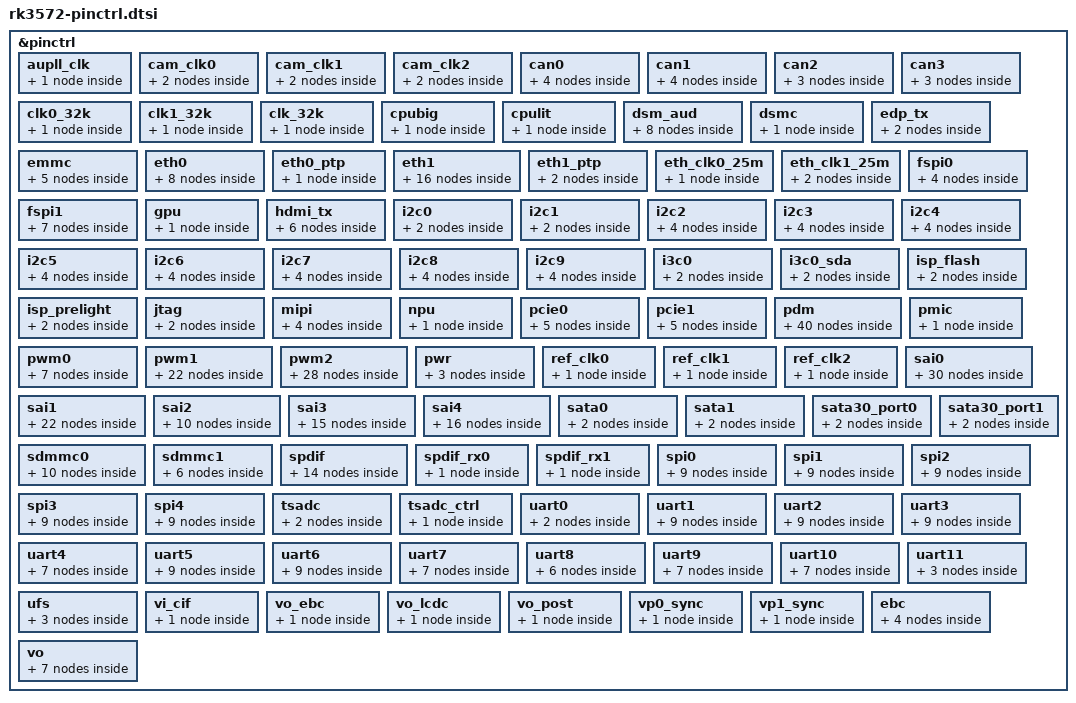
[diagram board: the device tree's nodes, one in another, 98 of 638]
// SPDX-License-Identifier: (GPL-2.0+ OR MIT)
/*
 * Copyright (c) 2025 Rockchip Electronics Co., Ltd.
 */

#include <dt-bindings/pinctrl/rockchip.h>
#include "rockchip-pinconf.dtsi"

&pinctrl {
	aupll_clk {
		/omit-if-no-ref/
		aupll_clk_pins: aupll-clk-pins {
			rockchip,pins =
				<0 RK_PA0 3 &pcfg_pull_none>;
		};
	};

	cam_clk0 {
		/omit-if-no-ref/
		cam_clk0m0_clk0_pins: cam-clk0m0-clk0-pins {
			rockchip,pins =
				<3 RK_PD7 1 &pcfg_pull_none>;
		};

		/omit-if-no-ref/
		cam_clk0m1_clk0_pins: cam-clk0m1-clk0-pins {
			rockchip,pins =
				<2 RK_PD4 3 &pcfg_pull_none>;
		};
	};

	cam_clk1 {
		/omit-if-no-ref/
		cam_clk1m0_clk1_pins: cam-clk1m0-clk1-pins {
			rockchip,pins =
				<4 RK_PA0 1 &pcfg_pull_none>;
		};

		/omit-if-no-ref/
		cam_clk1m1_clk1_pins: cam-clk1m1-clk1-pins {
			rockchip,pins =
				<2 RK_PD5 3 &pcfg_pull_none>;
		};
	};

	cam_clk2 {
		/omit-if-no-ref/
		cam_clk2m0_clk2_pins: cam-clk2m0-clk2-pins {
			rockchip,pins =
				<4 RK_PA1 1 &pcfg_pull_none>;
		};

		/omit-if-no-ref/
		cam_clk2m1_clk2_pins: cam-clk2m1-clk2-pins {
			rockchip,pins =
				<2 RK_PD6 3 &pcfg_pull_none>;
		};
	};

	can0 {
		/omit-if-no-ref/
		can0m0_pins: can0m0-pins {
			rockchip,pins =
				<2 RK_PA2 13 &pcfg_pull_none>,
				<2 RK_PA3 13 &pcfg_pull_none>;
		};

		/omit-if-no-ref/
		can0m1_pins: can0m1-pins {
			rockchip,pins =
				<4 RK_PB3 14 &pcfg_pull_none>,
				<4 RK_PB2 14 &pcfg_pull_none>;
		};

		/omit-if-no-ref/
		can0m2_pins: can0m2-pins {
			rockchip,pins =
				<2 RK_PB3 13 &pcfg_pull_none>,
				<2 RK_PB1 13 &pcfg_pull_none>;
		};

		/omit-if-no-ref/
		can0m3_pins: can0m3-pins {
			rockchip,pins =
				<3 RK_PC1 13 &pcfg_pull_none>,
				<3 RK_PC4 13 &pcfg_pull_none>;
		};
	};

	can1 {
		/omit-if-no-ref/
		can1m0_pins: can1m0-pins {
			rockchip,pins =
				<2 RK_PA0 13 &pcfg_pull_none>,
				<2 RK_PA1 13 &pcfg_pull_none>;
		};

		/omit-if-no-ref/
		can1m1_pins: can1m1-pins {
			rockchip,pins =
				<4 RK_PB7 13 &pcfg_pull_none>,
				<4 RK_PB6 13 &pcfg_pull_none>;
		};

		/omit-if-no-ref/
		can1m2_pins: can1m2-pins {
			rockchip,pins =
				<2 RK_PC2 13 &pcfg_pull_none>,
				<2 RK_PC3 13 &pcfg_pull_none>;
		};

		/omit-if-no-ref/
		can1m3_pins: can1m3-pins {
			rockchip,pins =
				<2 RK_PD7 13 &pcfg_pull_none>,
				<2 RK_PD6 13 &pcfg_pull_none>;
		};
	};

	can2 {
		/omit-if-no-ref/
		can2m0_pins: can2m0-pins {
			rockchip,pins =
				<2 RK_PA4 13 &pcfg_pull_none>,
				<2 RK_PA5 13 &pcfg_pull_none>;
		};

		/omit-if-no-ref/
		can2m1_pins: can2m1-pins {
			rockchip,pins =
				<1 RK_PC2 13 &pcfg_pull_none>,
				<1 RK_PC3 13 &pcfg_pull_none>;
		};

		/omit-if-no-ref/
		can2m2_pins: can2m2-pins {
			rockchip,pins =
				<3 RK_PB7 13 &pcfg_pull_none>,
				<3 RK_PC0 13 &pcfg_pull_none>;
		};
	};

	can3 {
		/omit-if-no-ref/
		can3m0_pins: can3m0-pins {
			rockchip,pins =
				<1 RK_PD6 13 &pcfg_pull_none>,
				<1 RK_PD5 13 &pcfg_pull_none>;
		};

		/omit-if-no-ref/
		can3m1_pins: can3m1-pins {
			rockchip,pins =
				<2 RK_PD5 13 &pcfg_pull_none>,
				<2 RK_PD4 13 &pcfg_pull_none>;
		};

		/omit-if-no-ref/
		can3m2_pins: can3m2-pins {
			rockchip,pins =
				<3 RK_PC2 13 &pcfg_pull_none>,
				<3 RK_PC3 13 &pcfg_pull_none>;
		};
	};

	clk0_32k {
		/omit-if-no-ref/
		clk0_32k_pins: clk0-32k-pins {
			rockchip,pins =
				<0 RK_PA2 10 &pcfg_pull_none>;
		};
	};

	clk1_32k {
		/omit-if-no-ref/
		clk1_32k_pins: clk1-32k-pins {
			rockchip,pins =
				<1 RK_PD5 7 &pcfg_pull_none>;
		};
	};

	clk_32k {
		/omit-if-no-ref/
		clk_32k_pins: clk-32k-pins {
			rockchip,pins =
				<0 RK_PA2 9 &pcfg_pull_none>;
		};
	};

	cpubig {
		/omit-if-no-ref/
		cpubig_pins: cpubig-pins {
			rockchip,pins =
				<0 RK_PD2 13 &pcfg_pull_none>;
		};
	};

	cpulit {
		/omit-if-no-ref/
		cpulit_pins: cpulit-pins {
			rockchip,pins =
				<0 RK_PC0 13 &pcfg_pull_none>;
		};
	};

	dsm_aud {
		/omit-if-no-ref/
		dsm_audm0_ln_pins: dsm-audm0-ln-pins {
			rockchip,pins =
				<2 RK_PA1 3 &pcfg_pull_none>;
		};

		/omit-if-no-ref/
		dsm_audm0_lp_pins: dsm-audm0-lp-pins {
			rockchip,pins =
				<2 RK_PA0 3 &pcfg_pull_none>;
		};

		/omit-if-no-ref/
		dsm_audm0_rn_pins: dsm-audm0-rn-pins {
			rockchip,pins =
				<2 RK_PA3 3 &pcfg_pull_none>;
		};

		/omit-if-no-ref/
		dsm_audm0_rp_pins: dsm-audm0-rp-pins {
			rockchip,pins =
				<2 RK_PA2 3 &pcfg_pull_none>;
		};

		/omit-if-no-ref/
		dsm_audm1_ln_pins: dsm-audm1-ln-pins {
			rockchip,pins =
				<4 RK_PB1 3 &pcfg_pull_none>;
		};

		/omit-if-no-ref/
		dsm_audm1_lp_pins: dsm-audm1-lp-pins {
			rockchip,pins =
				<4 RK_PB0 3 &pcfg_pull_none>;
		};

		/omit-if-no-ref/
		dsm_audm1_rn_pins: dsm-audm1-rn-pins {
			rockchip,pins =
				<4 RK_PB3 3 &pcfg_pull_none>;
		};

		/omit-if-no-ref/
		dsm_audm1_rp_pins: dsm-audm1-rp-pins {
			rockchip,pins =
				<4 RK_PB2 3 &pcfg_pull_none>;
		};
	};

	dsmc {
		/omit-if-no-ref/
		dsmc_bus16_pins: dsmc-bus16-pins {
			rockchip,pins =
				<3 RK_PD6 2 &pcfg_pull_none>,
				<3 RK_PD5 2 &pcfg_pull_none>,
				<3 RK_PD3 2 &pcfg_pull_none>,
				<3 RK_PB0 2 &pcfg_pull_none>,
				<3 RK_PD1 2 &pcfg_pull_none>,
				<3 RK_PD2 2 &pcfg_pull_none>,
				<3 RK_PD4 2 &pcfg_pull_none>,
				<3 RK_PD0 2 &pcfg_pull_none>,
				<3 RK_PC7 2 &pcfg_pull_none>,
				<3 RK_PC6 2 &pcfg_pull_none>,
				<3 RK_PC5 2 &pcfg_pull_none>,
				<3 RK_PC4 2 &pcfg_pull_none>,
				<3 RK_PC1 2 &pcfg_pull_none>,
				<3 RK_PC0 2 &pcfg_pull_none>,
				<3 RK_PB5 2 &pcfg_pull_none>,
				<3 RK_PB4 2 &pcfg_pull_none>,
				<3 RK_PB3 2 &pcfg_pull_none>,
				<3 RK_PB2 2 &pcfg_pull_none>,
				<3 RK_PB1 2 &pcfg_pull_none>,
				<3 RK_PA7 2 &pcfg_pull_none>,
				<3 RK_PA6 2 &pcfg_pull_none>,
				<3 RK_PA5 2 &pcfg_pull_none>,
				<3 RK_PB7 2 &pcfg_pull_none>,
				<3 RK_PB6 2 &pcfg_pull_none>,
				<4 RK_PA0 2 &pcfg_pull_none>,
				<3 RK_PC2 2 &pcfg_pull_none>,
				<4 RK_PA1 2 &pcfg_pull_none>,
				<3 RK_PC3 2 &pcfg_pull_none>,
				<3 RK_PA4 2 &pcfg_pull_none>,
				<3 RK_PD7 2 &pcfg_pull_none>;
		};
	};

	edp_tx {
		/omit-if-no-ref/
		edp_txm0_pins: edp-txm0-pins {
			rockchip,pins =
				<4 RK_PB1 10 &pcfg_pull_none>;
		};

		/omit-if-no-ref/
		edp_txm1_pins: edp-txm1-pins {
			rockchip,pins =
				<0 RK_PB6 10 &pcfg_pull_none>;
		};
	};

	emmc {
		/omit-if-no-ref/
		emmc_rstnout_pins: emmc-rstnout-pins {
			rockchip,pins =
				<1 RK_PB3 1 &pcfg_pull_none>;
		};

		/omit-if-no-ref/
		emmc_bus8_pins: emmc-bus8-pins {
			rockchip,pins =
				<1 RK_PA0 1 &pcfg_pull_up_drv_level_2>,
				<1 RK_PA1 1 &pcfg_pull_up_drv_level_2>,
				<1 RK_PA2 1 &pcfg_pull_up_drv_level_2>,
				<1 RK_PA3 1 &pcfg_pull_up_drv_level_2>,
				<1 RK_PA4 1 &pcfg_pull_up_drv_level_2>,
				<1 RK_PA5 1 &pcfg_pull_up_drv_level_2>,
				<1 RK_PA6 1 &pcfg_pull_up_drv_level_2>,
				<1 RK_PA7 1 &pcfg_pull_up_drv_level_2>;
		};

		/omit-if-no-ref/
		emmc_clk_pins: emmc-clk-pins {
			rockchip,pins =
				<1 RK_PB1 1 &pcfg_pull_up_drv_level_2>;
		};

		/omit-if-no-ref/
		emmc_cmd_pins: emmc-cmd-pins {
			rockchip,pins =
				<1 RK_PB0 1 &pcfg_pull_up_drv_level_2>;
		};

		/omit-if-no-ref/
		emmc_strb_pins: emmc-strb-pins {
			rockchip,pins =
				<1 RK_PB2 1 &pcfg_pull_none>;
		};
	};

	eth0 {
		/omit-if-no-ref/
		eth0_miim_pins: eth0-miim-pins {
			rockchip,pins =
				<2 RK_PC6 1 &pcfg_pull_none>,
				<2 RK_PC5 1 &pcfg_pull_none>;
		};

		/omit-if-no-ref/
		eth0_rx_bus2_pins: eth0-rx-bus2-pins {
			rockchip,pins =
				<2 RK_PC7 1 &pcfg_pull_none>,
				<2 RK_PD2 1 &pcfg_pull_none>,
				<2 RK_PD1 1 &pcfg_pull_none>;
		};

		/omit-if-no-ref/
		eth0_tx_bus2_pins: eth0-tx-bus2-pins {
			rockchip,pins =
				<2 RK_PD3 1 &pcfg_pull_none>,
				<2 RK_PD4 1 &pcfg_pull_none>,
				<2 RK_PD5 1 &pcfg_pull_none>;
		};

		/omit-if-no-ref/
		eth0_rgmii_clk_pins: eth0-rgmii-clk-pins {
			rockchip,pins =
				<2 RK_PD7 1 &pcfg_pull_none>,
				<2 RK_PD6 1 &pcfg_pull_none>;
		};

		/omit-if-no-ref/
		eth0_rgmii_bus_pins: eth0-rgmii-bus-pins {
			rockchip,pins =
				<2 RK_PC1 1 &pcfg_pull_none>,
				<2 RK_PC0 1 &pcfg_pull_none>,
				<2 RK_PC2 1 &pcfg_pull_none>,
				<2 RK_PC3 1 &pcfg_pull_none>;
		};

		/omit-if-no-ref/
		eth0_mclk_pins: eth0-mclk-pins {
			rockchip,pins =
				<2 RK_PD0 1 &pcfg_pull_none>;
		};

		/omit-if-no-ref/
		eth0_ppsclk_pins: eth0-ppsclk-pins {
			rockchip,pins =
				<2 RK_PB6 1 &pcfg_pull_none>;
		};

		/omit-if-no-ref/
		eth0_ppstrig_pins: eth0-ppstrig-pins {
			rockchip,pins =
				<2 RK_PB7 1 &pcfg_pull_none>;
		};
	};

	eth0_ptp {
		/omit-if-no-ref/
		eth0_ptp_refclk_pins: eth0-ptp-refclk-pins {
			rockchip,pins =
				<2 RK_PB5 1 &pcfg_pull_none>;
		};
	};

	eth1 {
		/omit-if-no-ref/
		eth1m0_miim_pins: eth1m0-miim-pins {
			rockchip,pins =
				<3 RK_PA6 1 &pcfg_pull_none>,
				<3 RK_PA5 1 &pcfg_pull_none>;
		};

		/omit-if-no-ref/
		eth1m0_rx_bus2_pins: eth1m0-rx-bus2-pins {
			rockchip,pins =
				<3 RK_PA7 1 &pcfg_pull_none>,
				<3 RK_PB2 1 &pcfg_pull_none>,
				<3 RK_PB1 1 &pcfg_pull_none>;
		};

		/omit-if-no-ref/
		eth1m0_tx_bus2_pins: eth1m0-tx-bus2-pins {
			rockchip,pins =
				<3 RK_PB3 1 &pcfg_pull_none>,
				<3 RK_PB5 1 &pcfg_pull_none>,
				<3 RK_PB4 1 &pcfg_pull_none>;
		};

		/omit-if-no-ref/
		eth1m0_rgmii_clk_pins: eth1m0-rgmii-clk-pins {
			rockchip,pins =
				<3 RK_PD1 1 &pcfg_pull_none>,
				<3 RK_PB6 1 &pcfg_pull_none>;
		};

		/omit-if-no-ref/
		eth1m0_rgmii_bus_pins: eth1m0-rgmii-bus-pins {
			rockchip,pins =
				<3 RK_PD3 1 &pcfg_pull_none>,
				<3 RK_PD2 1 &pcfg_pull_none>,
				<3 RK_PC3 1 &pcfg_pull_none>,
				<3 RK_PC2 1 &pcfg_pull_none>;
		};

		/omit-if-no-ref/
		eth1m0_mclk_pins: eth1m0-mclk-pins {
			rockchip,pins =
				<3 RK_PB0 1 &pcfg_pull_none>;
		};

		/omit-if-no-ref/
		eth1m0_ppsclk_pins: eth1m0-ppsclk-pins {
			rockchip,pins =
				<3 RK_PC0 1 &pcfg_pull_none>;
		};

		/omit-if-no-ref/
		eth1m0_ppstrig_pins: eth1m0-ppstrig-pins {
			rockchip,pins =
				<3 RK_PB7 1 &pcfg_pull_none>;
		};

		/omit-if-no-ref/
		eth1m1_miim_pins: eth1m1-miim-pins {
			rockchip,pins =
				<1 RK_PD2 1 &pcfg_pull_none>,
				<1 RK_PD3 1 &pcfg_pull_none>;
		};

		/omit-if-no-ref/
		eth1m1_rx_bus2_pins: eth1m1-rx-bus2-pins {
			rockchip,pins =
				<1 RK_PD1 1 &pcfg_pull_none>,
				<1 RK_PC7 1 &pcfg_pull_none>,
				<1 RK_PD0 1 &pcfg_pull_none>;
		};

		/omit-if-no-ref/
		eth1m1_tx_bus2_pins: eth1m1-tx-bus2-pins {
			rockchip,pins =
				<1 RK_PC6 1 &pcfg_pull_none>,
				<1 RK_PC4 1 &pcfg_pull_none>,
				<1 RK_PC5 1 &pcfg_pull_none>;
		};

		/omit-if-no-ref/
		eth1m1_rgmii_clk_pins: eth1m1-rgmii-clk-pins {
			rockchip,pins =
				<1 RK_PB6 1 &pcfg_pull_none>,
				<1 RK_PC1 1 &pcfg_pull_none>;
		};

		/omit-if-no-ref/
		eth1m1_rgmii_bus_pins: eth1m1-rgmii-bus-pins {
			rockchip,pins =
				<1 RK_PB4 1 &pcfg_pull_none>,
				<1 RK_PB5 1 &pcfg_pull_none>,
				<1 RK_PB7 1 &pcfg_pull_none>,
				<1 RK_PC0 1 &pcfg_pull_none>;
		};

		/omit-if-no-ref/
		eth1m1_mclk_pins: eth1m1-mclk-pins {
			rockchip,pins =
				<1 RK_PD4 1 &pcfg_pull_none>;
		};

		/omit-if-no-ref/
		eth1m1_ppsclk_pins: eth1m1-ppsclk-pins {
			rockchip,pins =
				<1 RK_PC2 1 &pcfg_pull_none>;
		};

		/omit-if-no-ref/
		eth1m1_ppstrig_pins: eth1m1-ppstrig-pins {
			rockchip,pins =
				<1 RK_PC3 1 &pcfg_pull_none>;
		};
	};

	eth1_ptp {
		/omit-if-no-ref/
		eth1m0_ptp_refclk_pins: eth1m0-ptp-refclk-pins {
			rockchip,pins =
				<3 RK_PC1 1 &pcfg_pull_none>;
		};

		/omit-if-no-ref/
		eth1m1_ptp_refclk_pins: eth1m1-ptp-refclk-pins {
			rockchip,pins =
				<1 RK_PD6 1 &pcfg_pull_none>;
		};
	};

	eth_clk0_25m {
		/omit-if-no-ref/
		eth_clk0_25m_out_pins: eth-clk0-25m-out-pins {
			rockchip,pins =
				<2 RK_PC4 1 &pcfg_pull_none>;
		};
	};

	eth_clk1_25m {
		/omit-if-no-ref/
		ethm0_clk1_25m_out_pins: ethm0-clk1-25m-out-pins {
			rockchip,pins =
				<3 RK_PA4 1 &pcfg_pull_none>;
		};

		/omit-if-no-ref/
		ethm1_clk1_25m_out_pins: ethm1-clk1-25m-out-pins {
			rockchip,pins =
				<1 RK_PD5 1 &pcfg_pull_none>;
		};
	};

	fspi0 {
		/omit-if-no-ref/
		fspi0_pins: fspi0-pins {
			rockchip,pins =
				<1 RK_PB1 2 &pcfg_pull_none>,
				<1 RK_PA0 2 &pcfg_pull_none>,
				<1 RK_PA1 2 &pcfg_pull_none>,
				<1 RK_PA2 2 &pcfg_pull_none>,
				<1 RK_PA3 2 &pcfg_pull_none>,
				<1 RK_PA4 2 &pcfg_pull_none>,
				<1 RK_PA5 2 &pcfg_pull_none>,
				<1 RK_PA6 2 &pcfg_pull_none>,
				<1 RK_PA7 2 &pcfg_pull_none>,
				<1 RK_PB2 2 &pcfg_pull_none>;
		};

		/omit-if-no-ref/
		fspi0_csn0_pins: fspi0-csn0-pins {
			rockchip,pins =
				<1 RK_PB3 2 &pcfg_pull_none>;
		};

		/omit-if-no-ref/
		fspi0_csn1_pins: fspi0-csn1-pins {
			rockchip,pins =
				<1 RK_PB0 2 &pcfg_pull_none>;
		};

		/omit-if-no-ref/
		fspi0_rst_pins: fspi0-rst-pins {
			rockchip,pins =
				<1 RK_PB0 3 &pcfg_pull_none>;
		};
	};

	fspi1 {
		/omit-if-no-ref/
		fspi1m0_pins: fspi1m0-pins {
			rockchip,pins =
				<2 RK_PA5 1 &pcfg_pull_none>,
				<2 RK_PA0 1 &pcfg_pull_none>,
				<2 RK_PA1 1 &pcfg_pull_none>,
				<2 RK_PA2 1 &pcfg_pull_none>,
				<2 RK_PA3 1 &pcfg_pull_none>;
		};

		/omit-if-no-ref/
		fspi1m0_csn0_pins: fspi1m0-csn0-pins {
			rockchip,pins =
				<2 RK_PA4 1 &pcfg_pull_none>;
		};

		/omit-if-no-ref/
		fspi1m1_pins: fspi1m1-pins {
			rockchip,pins =
				<2 RK_PD5 2 &pcfg_pull_none>,
				<2 RK_PD3 2 &pcfg_pull_none>,
				<2 RK_PD2 2 &pcfg_pull_none>,
				<2 RK_PD1 2 &pcfg_pull_none>,
				<2 RK_PD0 2 &pcfg_pull_none>,
				<2 RK_PC7 2 &pcfg_pull_none>,
				<2 RK_PC6 2 &pcfg_pull_none>,
				<2 RK_PC5 2 &pcfg_pull_none>,
				<2 RK_PC4 2 &pcfg_pull_none>;
		};

		/omit-if-no-ref/
		fspi1m1_csn0_pins: fspi1m1-csn0-pins {
			rockchip,pins =
				<2 RK_PD6 2 &pcfg_pull_none>;
		};

		/omit-if-no-ref/
		fspi1m1_csn1_pins: fspi1m1-csn1-pins {
			rockchip,pins =
				<2 RK_PD7 2 &pcfg_pull_none>;
		};

		/omit-if-no-ref/
		fspi1_pins: fspi1-pins {
			rockchip,pins =
				<2 RK_PD4 2 &pcfg_pull_none>;
		};

		/omit-if-no-ref/
		fspi1_rst_pins: fspi1-rst-pins {
			rockchip,pins =
				<2 RK_PD7 3 &pcfg_pull_none>;
		};
	};

	gpu {
		/omit-if-no-ref/
		gpu_pins: gpu-pins {
			rockchip,pins =
				<0 RK_PD3 13 &pcfg_pull_none>;
		};
	};

	hdmi_tx {
		/omit-if-no-ref/
		hdmi_txm0_cec_pins: hdmi-txm0-cec-pins {
			rockchip,pins =
				<4 RK_PB0 13 &pcfg_pull_none>;
		};

		/omit-if-no-ref/
		hdmi_txm0_hpdin_pins: hdmi-txm0-hpdin-pins {
			rockchip,pins =
				<4 RK_PB1 13 &pcfg_pull_none>;
		};

		/omit-if-no-ref/
		hdmi_txm0_ddc_pins: hdmi-txm0-ddc-pins {
			rockchip,pins =
				<4 RK_PB2 13 &pcfg_pull_none>,
				<4 RK_PB3 13 &pcfg_pull_none>;
		};

		/omit-if-no-ref/
		hdmi_txm1_cec_pins: hdmi-txm1-cec-pins {
			rockchip,pins =
				<0 RK_PC3 9 &pcfg_pull_none>;
		};

		/omit-if-no-ref/
		hdmi_txm1_hpdin_pins: hdmi-txm1-hpdin-pins {
			rockchip,pins =
				<0 RK_PB6 9 &pcfg_pull_none>;
		};

		/omit-if-no-ref/
		hdmi_txm1_ddc_pins: hdmi-txm1-ddc-pins {
			rockchip,pins =
				<1 RK_PC6 14 &pcfg_pull_none>,
				<1 RK_PC7 14 &pcfg_pull_none>;
		};
	};

	i2c0 {
		/omit-if-no-ref/
		i2c0m0_xfer_pins: i2c0m0-xfer-pins {
			rockchip,pins =
				<0 RK_PB0 11 &pcfg_pull_none_smt>,
				<0 RK_PB1 11 &pcfg_pull_none_smt>;
		};

		/omit-if-no-ref/
		i2c0m1_xfer_pins: i2c0m1-xfer-pins {
			rockchip,pins =
				<0 RK_PC1 11 &pcfg_pull_none_smt>,
				<0 RK_PC2 11 &pcfg_pull_none_smt>;
		};
	};

	i2c1 {
		/omit-if-no-ref/
		i2c1m0_xfer_pins: i2c1m0-xfer-pins {
			rockchip,pins =
				<0 RK_PB2 11 &pcfg_pull_none_smt>,
				<0 RK_PB3 11 &pcfg_pull_none_smt>;
		};

		/omit-if-no-ref/
		i2c1m1_xfer_pins: i2c1m1-xfer-pins {
			rockchip,pins =
				<0 RK_PB4 11 &pcfg_pull_none_smt>,
				<0 RK_PB5 11 &pcfg_pull_none_smt>;
		};
	};

	i2c2 {
		/omit-if-no-ref/
		i2c2m0_xfer_pins: i2c2m0-xfer-pins {
			rockchip,pins =
				<0 RK_PB7 11 &pcfg_pull_none_smt>,
				<0 RK_PC0 11 &pcfg_pull_none_smt>;
		};

		/omit-if-no-ref/
		i2c2m1_xfer_pins: i2c2m1-xfer-pins {
			rockchip,pins =
				<1 RK_PA0 11 &pcfg_pull_none_smt>,
				<1 RK_PA1 11 &pcfg_pull_none_smt>;
		};

		/omit-if-no-ref/
		i2c2m2_xfer_pins: i2c2m2-xfer-pins {
			rockchip,pins =
				<2 RK_PB1 11 &pcfg_pull_none_smt>,
				<2 RK_PB3 11 &pcfg_pull_none_smt>;
		};

		/omit-if-no-ref/
		i2c2m3_xfer_pins: i2c2m3-xfer-pins {
			rockchip,pins =
				<4 RK_PB2 11 &pcfg_pull_none_smt>,
				<4 RK_PB3 11 &pcfg_pull_none_smt>;
		};
	};

	i2c3 {
		/omit-if-no-ref/
		i2c3m0_xfer_pins: i2c3m0-xfer-pins {
			rockchip,pins =
				<2 RK_PC3 11 &pcfg_pull_none_smt>,
				<2 RK_PC2 11 &pcfg_pull_none_smt>;
		};

		/omit-if-no-ref/
		i2c3m1_xfer_pins: i2c3m1-xfer-pins {
			rockchip,pins =
				<0 RK_PC6 11 &pcfg_pull_none_smt>,
				<0 RK_PC7 11 &pcfg_pull_none_smt>;
		};

		/omit-if-no-ref/
		i2c3m2_xfer_pins: i2c3m2-xfer-pins {
			rockchip,pins =
				<3 RK_PD4 11 &pcfg_pull_none_smt>,
				<3 RK_PD5 11 &pcfg_pull_none_smt>;
		};

		/omit-if-no-ref/
		i2c3m3_xfer_pins: i2c3m3-xfer-pins {
			rockchip,pins =
				<4 RK_PB0 11 &pcfg_pull_none_smt>,
				<4 RK_PB1 11 &pcfg_pull_none_smt>;
		};
	};

	i2c4 {
		/omit-if-no-ref/
		i2c4m0_xfer_pins: i2c4m0-xfer-pins {
			rockchip,pins =
				<0 RK_PD2 11 &pcfg_pull_none_smt>,
				<0 RK_PD3 11 &pcfg_pull_none_smt>;
		};

		/omit-if-no-ref/
		i2c4m1_xfer_pins: i2c4m1-xfer-pins {
			rockchip,pins =
				<2 RK_PB2 11 &pcfg_pull_none_smt>,
				<2 RK_PB4 11 &pcfg_pull_none_smt>;
		};

		/omit-if-no-ref/
		i2c4m2_xfer_pins: i2c4m2-xfer-pins {
			rockchip,pins =
				<2 RK_PD6 11 &pcfg_pull_none_smt>,
				<2 RK_PD7 11 &pcfg_pull_none_smt>;
		};

		/omit-if-no-ref/
		i2c4m3_xfer_pins: i2c4m3-xfer-pins {
			rockchip,pins =
				<3 RK_PC0 11 &pcfg_pull_none_smt>,
				<3 RK_PB7 11 &pcfg_pull_none_smt>;
		};
	};

	i2c5 {
		/omit-if-no-ref/
		i2c5m0_xfer_pins: i2c5m0-xfer-pins {
			rockchip,pins =
				<2 RK_PA5 11 &pcfg_pull_none_smt>,
				<2 RK_PA4 11 &pcfg_pull_none_smt>;
		};

		/omit-if-no-ref/
		i2c5m1_xfer_pins: i2c5m1-xfer-pins {
			rockchip,pins =
				<1 RK_PD4 11 &pcfg_pull_none_smt>,
				<1 RK_PD5 11 &pcfg_pull_none_smt>;
		};

		/omit-if-no-ref/
		i2c5m2_xfer_pins: i2c5m2-xfer-pins {
			rockchip,pins =
				<2 RK_PD4 11 &pcfg_pull_none_smt>,
				<2 RK_PD5 11 &pcfg_pull_none_smt>;
		};

		/omit-if-no-ref/
		i2c5m3_xfer_pins: i2c5m3-xfer-pins {
			rockchip,pins =
				<3 RK_PC4 11 &pcfg_pull_none_smt>,
				<3 RK_PC1 11 &pcfg_pull_none_smt>;
		};
	};

	i2c6 {
		/omit-if-no-ref/
		i2c6m0_xfer_pins: i2c6m0-xfer-pins {
			rockchip,pins =
				<0 RK_PA2 11 &pcfg_pull_none_smt>,
				<0 RK_PA5 11 &pcfg_pull_none_smt>;
		};

		/omit-if-no-ref/
		i2c6m1_xfer_pins: i2c6m1-xfer-pins {
			rockchip,pins =
				<1 RK_PC2 11 &pcfg_pull_none_smt>,
				<1 RK_PC3 11 &pcfg_pull_none_smt>;
		};

		/omit-if-no-ref/
		i2c6m2_xfer_pins: i2c6m2-xfer-pins {
			rockchip,pins =
				<2 RK_PD2 11 &pcfg_pull_none_smt>,
				<2 RK_PD3 11 &pcfg_pull_none_smt>;
		};

		/omit-if-no-ref/
		i2c6m3_xfer_pins: i2c6m3-xfer-pins {
			rockchip,pins =
				<4 RK_PB6 11 &pcfg_pull_none_smt>,
				<4 RK_PB7 11 &pcfg_pull_none_smt>;
		};
	};

	i2c7 {
		/omit-if-no-ref/
		i2c7m0_xfer_pins: i2c7m0-xfer-pins {
			rockchip,pins =
				<1 RK_PB0 11 &pcfg_pull_none_smt>,
				<1 RK_PB3 11 &pcfg_pull_none_smt>;
		};

		/omit-if-no-ref/
		i2c7m1_xfer_pins: i2c7m1-xfer-pins {
			rockchip,pins =
				<2 RK_PD0 11 &pcfg_pull_none_smt>,
				<2 RK_PD1 11 &pcfg_pull_none_smt>;
		};

		/omit-if-no-ref/
		i2c7m2_xfer_pins: i2c7m2-xfer-pins {
			rockchip,pins =
				<4 RK_PA0 11 &pcfg_pull_none_smt>,
				<4 RK_PA1 11 &pcfg_pull_none_smt>;
		};

		/omit-if-no-ref/
		i2c7m3_xfer_pins: i2c7m3-xfer-pins {
			rockchip,pins =
				<4 RK_PB4 11 &pcfg_pull_none_smt>,
				<4 RK_PB5 11 &pcfg_pull_none_smt>;
		};
	};

	i2c8 {
		/omit-if-no-ref/
		i2c8m0_xfer_pins: i2c8m0-xfer-pins {
			rockchip,pins =
				<2 RK_PA0 11 &pcfg_pull_none_smt>,
				<2 RK_PA1 11 &pcfg_pull_none_smt>;
		};

		/omit-if-no-ref/
		i2c8m1_xfer_pins: i2c8m1-xfer-pins {
			rockchip,pins =
				<1 RK_PC6 11 &pcfg_pull_none_smt>,
				<1 RK_PC7 11 &pcfg_pull_none_smt>;
		};

		/omit-if-no-ref/
		i2c8m2_xfer_pins: i2c8m2-xfer-pins {
			rockchip,pins =
				<2 RK_PC4 11 &pcfg_pull_none_smt>,
				<2 RK_PC5 11 &pcfg_pull_none_smt>;
		};

		/omit-if-no-ref/
		i2c8m3_xfer_pins: i2c8m3-xfer-pins {
			rockchip,pins =
				<3 RK_PB3 11 &pcfg_pull_none_smt>,
				<3 RK_PB2 11 &pcfg_pull_none_smt>;
		};
	};

	i2c9 {
		/omit-if-no-ref/
		i2c9m0_xfer_pins: i2c9m0-xfer-pins {
			rockchip,pins =
				<1 RK_PA5 11 &pcfg_pull_none_smt>,
				<1 RK_PA6 11 &pcfg_pull_none_smt>;
		};

		/omit-if-no-ref/
		i2c9m1_xfer_pins: i2c9m1-xfer-pins {
			rockchip,pins =
				<1 RK_PB5 11 &pcfg_pull_none_smt>,
				<1 RK_PB4 11 &pcfg_pull_none_smt>;
		};

		/omit-if-no-ref/
		i2c9m2_xfer_pins: i2c9m2-xfer-pins {
			rockchip,pins =
				<2 RK_PC7 11 &pcfg_pull_none_smt>,
				<2 RK_PC6 11 &pcfg_pull_none_smt>;
		};

		/omit-if-no-ref/
		i2c9m3_xfer_pins: i2c9m3-xfer-pins {
			rockchip,pins =
				<3 RK_PC2 11 &pcfg_pull_none_smt>,
				<3 RK_PC3 11 &pcfg_pull_none_smt>;
		};
	};

	i3c0 {
		/omit-if-no-ref/
		i3c0m0_xfer_pins: i3c0m0-xfer-pins {
			rockchip,pins =
				<0 RK_PC1 12 &pcfg_pull_none_smt>,
				<0 RK_PC2 12 &pcfg_pull_none_smt>;
		};

		/omit-if-no-ref/
		i3c0m1_xfer_pins: i3c0m1-xfer-pins {
			rockchip,pins =
				<1 RK_PD2 11 &pcfg_pull_none_smt>,
				<1 RK_PD3 11 &pcfg_pull_none_smt>;
		};
	};

	i3c0_sda {
		/omit-if-no-ref/
		i3c0_sdam0_pu_pins: i3c0-sdam0-pu-pins {
			rockchip,pins =
				<0 RK_PC5 12 &pcfg_pull_none>;
		};

		/omit-if-no-ref/
		i3c0_sdam1_pu_pins: i3c0-sdam1-pu-pins {
			rockchip,pins =
				<1 RK_PD1 11 &pcfg_pull_none>;
		};
	};

	isp_flash {
		/omit-if-no-ref/
		isp_flashm0_pins: isp-flashm0-pins {
			rockchip,pins =
				<2 RK_PD0 7 &pcfg_pull_none>;
		};

		/omit-if-no-ref/
		isp_flashm1_pins: isp-flashm1-pins {
			rockchip,pins =
				<4 RK_PB5 1 &pcfg_pull_none>;
		};
	};

	isp_prelight {
		/omit-if-no-ref/
		isp_prelightm0_pins: isp-prelightm0-pins {
			rockchip,pins =
				<2 RK_PC7 7 &pcfg_pull_none>;
		};

		/omit-if-no-ref/
		isp_prelightm1_pins: isp-prelightm1-pins {
			rockchip,pins =
				<4 RK_PB4 1 &pcfg_pull_none>;
		};
	};

	jtag {
		/omit-if-no-ref/
		jtagm0_pins: jtagm0-pins {
			rockchip,pins =
				<2 RK_PA2 11 &pcfg_pull_none>,
				<2 RK_PA3 11 &pcfg_pull_none>;
		};

		/omit-if-no-ref/
		jtagm1_pins: jtagm1-pins {
			rockchip,pins =
				<0 RK_PD4 10 &pcfg_pull_none>,
				<0 RK_PD5 10 &pcfg_pull_none>;
		};
	};

	mipi {
		/omit-if-no-ref/
		mipim0_pins: mipim0-pins {
			rockchip,pins =
				<2 RK_PC2 12 &pcfg_pull_none>;
		};

		/omit-if-no-ref/
		mipim1_pins: mipim1-pins {
			rockchip,pins =
				<2 RK_PD6 14 &pcfg_pull_none>;
		};

		/omit-if-no-ref/
		mipim2_pins: mipim2-pins {
			rockchip,pins =
				<4 RK_PA0 13 &pcfg_pull_none>;
		};

		/omit-if-no-ref/
		mipim3_pins: mipim3-pins {
			rockchip,pins =
				<1 RK_PB3 13 &pcfg_pull_none>;
		};
	};

	npu {
		/omit-if-no-ref/
		npu_pins: npu-pins {
			rockchip,pins =
				<0 RK_PB7 13 &pcfg_pull_none>;
		};
	};

	pcie0 {
		/omit-if-no-ref/
		pcie0m0_pins: pcie0m0-pins {
			rockchip,pins =
				<2 RK_PD0 14 &pcfg_pull_up>;
		};

		/omit-if-no-ref/
		pcie0m1_pins: pcie0m1-pins {
			rockchip,pins =
				<1 RK_PB6 14 &pcfg_pull_up>;
		};

		/omit-if-no-ref/
		pcie0m2_pins: pcie0m2-pins {
			rockchip,pins =
				<2 RK_PC3 14 &pcfg_pull_up>;
		};

		/omit-if-no-ref/
		pcie0m3_pins: pcie0m3-pins {
			rockchip,pins =
				<4 RK_PB1 14 &pcfg_pull_up>;
		};

		/omit-if-no-ref/
		pcie0_buttonrstn_pins: pcie0-buttonrstn-pins {
			rockchip,pins =
				<1 RK_PC4 14 &pcfg_pull_none>;
		};
	};

	pcie1 {
		/omit-if-no-ref/
		pcie1m0_pins: pcie1m0-pins {
			rockchip,pins =
				<2 RK_PD1 14 &pcfg_pull_up>;
		};

		/omit-if-no-ref/
		pcie1m1_pins: pcie1m1-pins {
			rockchip,pins =
				<1 RK_PB4 14 &pcfg_pull_up>;
		};

		/omit-if-no-ref/
		pcie1m2_pins: pcie1m2-pins {
			rockchip,pins =
				<2 RK_PB3 14 &pcfg_pull_up>;
		};

		/omit-if-no-ref/
		pcie1m3_pins: pcie1m3-pins {
			rockchip,pins =
				<4 RK_PB6 14 &pcfg_pull_up>;
		};

		/omit-if-no-ref/
		pcie1_buttonrstn_pins: pcie1-buttonrstn-pins {
			rockchip,pins =
				<1 RK_PC5 14 &pcfg_pull_none>;
		};
	};

	pdm {
		/omit-if-no-ref/
		pdmm0_clk0_pins: pdmm0-clk0-pins {
			rockchip,pins =
				<0 RK_PC4 6 &pcfg_pull_none>;
		};

		/omit-if-no-ref/
		pdmm0_clk1_pins: pdmm0-clk1-pins {
			rockchip,pins =
				<0 RK_PC3 6 &pcfg_pull_none>;
		};

		/omit-if-no-ref/
		pdmm0_sdi0_pins: pdmm0-sdi0-pins {
			rockchip,pins =
				<0 RK_PD0 6 &pcfg_pull_none>;
		};

		/omit-if-no-ref/
		pdmm0_sdi1_pins: pdmm0-sdi1-pins {
			rockchip,pins =
				<0 RK_PD1 6 &pcfg_pull_none>;
		};

		/omit-if-no-ref/
		pdmm0_sdi2_pins: pdmm0-sdi2-pins {
			rockchip,pins =
				<0 RK_PD2 6 &pcfg_pull_none>;
		};

		/omit-if-no-ref/
		pdmm0_sdi3_pins: pdmm0-sdi3-pins {
			rockchip,pins =
				<0 RK_PD3 6 &pcfg_pull_none>;
		};

		/omit-if-no-ref/
		pdmm1_clk0_pins: pdmm1-clk0-pins {
			rockchip,pins =
				<2 RK_PB2 6 &pcfg_pull_none>;
		};

		/omit-if-no-ref/
		pdmm1_clk1_pins: pdmm1-clk1-pins {
			rockchip,pins =
				<2 RK_PB4 6 &pcfg_pull_none>;
		};

		/omit-if-no-ref/
		pdmm1_sdi0_pins: pdmm1-sdi0-pins {
			rockchip,pins =
				<2 RK_PC1 6 &pcfg_pull_none>;
		};

		/omit-if-no-ref/
		pdmm1_sdi1_pins: pdmm1-sdi1-pins {
			rockchip,pins =
				<2 RK_PC0 6 &pcfg_pull_none>;
		};

		/omit-if-no-ref/
		pdmm1_sdi2_pins: pdmm1-sdi2-pins {
			rockchip,pins =
				<2 RK_PB7 6 &pcfg_pull_none>;
		};

		/omit-if-no-ref/
		pdmm1_sdi3_pins: pdmm1-sdi3-pins {
			rockchip,pins =
				<2 RK_PB6 6 &pcfg_pull_none>;
		};

		/omit-if-no-ref/
		pdmm2_clk0_pins: pdmm2-clk0-pins {
			rockchip,pins =
				<1 RK_PC1 5 &pcfg_pull_none>;
		};

		/omit-if-no-ref/
		pdmm2_clk1_pins: pdmm2-clk1-pins {
			rockchip,pins =
				<1 RK_PD5 5 &pcfg_pull_none>;
		};

		/omit-if-no-ref/
		pdmm2_sdi0_pins: pdmm2-sdi0-pins {
			rockchip,pins =
				<1 RK_PC6 5 &pcfg_pull_none>;
		};

		/omit-if-no-ref/
		pdmm2_sdi1_pins: pdmm2-sdi1-pins {
			rockchip,pins =
				<1 RK_PC7 5 &pcfg_pull_none>;
		};

		/omit-if-no-ref/
		pdmm2_sdi2_pins: pdmm2-sdi2-pins {
			rockchip,pins =
				<1 RK_PC0 5 &pcfg_pull_none>;
		};

		/omit-if-no-ref/
		pdmm2_sdi3_pins: pdmm2-sdi3-pins {
			rockchip,pins =
				<1 RK_PD4 5 &pcfg_pull_none>;
		};

		/omit-if-no-ref/
		pdmm3_clk0_pins: pdmm3-clk0-pins {
			rockchip,pins =
				<2 RK_PC5 5 &pcfg_pull_none>;
		};

		/omit-if-no-ref/
		pdmm3_clk1_pins: pdmm3-clk1-pins {
			rockchip,pins =
				<2 RK_PC7 5 &pcfg_pull_none>;
		};

		/omit-if-no-ref/
		pdmm3_sdi0_pins: pdmm3-sdi0-pins {
			rockchip,pins =
				<2 RK_PC4 5 &pcfg_pull_none>;
		};

		/omit-if-no-ref/
		pdmm3_sdi1_pins: pdmm3-sdi1-pins {
			rockchip,pins =
				<2 RK_PC6 5 &pcfg_pull_none>;
		};

		/omit-if-no-ref/
		pdmm3_sdi2_pins: pdmm3-sdi2-pins {
			rockchip,pins =
				<2 RK_PD0 5 &pcfg_pull_none>;
		};

		/omit-if-no-ref/
		pdmm3_sdi3_pins: pdmm3-sdi3-pins {
			rockchip,pins =
				<2 RK_PD1 5 &pcfg_pull_none>;
		};

		/omit-if-no-ref/
		pdmm4_clk0_pins: pdmm4-clk0-pins {
			rockchip,pins =
				<3 RK_PB1 5 &pcfg_pull_none>;
		};

		/omit-if-no-ref/
		pdmm4_clk1_pins: pdmm4-clk1-pins {
			rockchip,pins =
				<3 RK_PA7 5 &pcfg_pull_none>;
		};

		/omit-if-no-ref/
		pdmm4_sdi0_pins: pdmm4-sdi0-pins {
			rockchip,pins =
				<3 RK_PB3 5 &pcfg_pull_none>;
		};

		/omit-if-no-ref/
		pdmm4_sdi1_pins: pdmm4-sdi1-pins {
			rockchip,pins =
				<3 RK_PB2 5 &pcfg_pull_none>;
		};

		/omit-if-no-ref/
		pdmm4_sdi2_pins: pdmm4-sdi2-pins {
			rockchip,pins =
				<3 RK_PA6 5 &pcfg_pull_none>;
		};

		/omit-if-no-ref/
		pdmm4_sdi3_pins: pdmm4-sdi3-pins {
			rockchip,pins =
				<3 RK_PA5 5 &pcfg_pull_none>;
		};
	};

	pmic {
		/omit-if-no-ref/
		pmic_pins: pmic-pins {
			rockchip,pins =
				<0 RK_PA6 9 &pcfg_pull_none>;
		};
	};

	pwm0 {
		/omit-if-no-ref/
		pwm0m0_ch0_pins: pwm0m0-ch0-pins {
			rockchip,pins =
				<0 RK_PC4 12 &pcfg_pull_none>;
		};

		/omit-if-no-ref/
		pwm0m0_ch1_pins: pwm0m0-ch1-pins {
			rockchip,pins =
				<0 RK_PC3 12 &pcfg_pull_none>;
		};

		/omit-if-no-ref/
		pwm0m1_ch0_pins: pwm0m1-ch0-pins {
			rockchip,pins =
				<1 RK_PC0 12 &pcfg_pull_none>;
		};

		/omit-if-no-ref/
		pwm0m1_ch1_pins: pwm0m1-ch1-pins {
			rockchip,pins =
				<4 RK_PB1 12 &pcfg_pull_none>;
		};

		/omit-if-no-ref/
		pwm0m2_ch0_pins: pwm0m2-ch0-pins {
			rockchip,pins =
				<2 RK_PD1 12 &pcfg_pull_none>;
		};

		/omit-if-no-ref/
		pwm0m2_ch1_pins: pwm0m2-ch1-pins {
			rockchip,pins =
				<3 RK_PB6 12 &pcfg_pull_none>;
		};

		/omit-if-no-ref/
		pwm0m3_ch0_pins: pwm0m3-ch0-pins {
			rockchip,pins =
				<3 RK_PB0 12 &pcfg_pull_none>;
		};
	};

	pwm1 {
		/omit-if-no-ref/
		pwm1m0_ch0_pins: pwm1m0-ch0-pins {
			rockchip,pins =
				<0 RK_PB4 12 &pcfg_pull_none>;
		};

		/omit-if-no-ref/
		pwm1m0_ch1_pins: pwm1m0-ch1-pins {
			rockchip,pins =
				<0 RK_PB5 12 &pcfg_pull_none>;
		};

		/omit-if-no-ref/
		pwm1m0_ch2_pins: pwm1m0-ch2-pins {
			rockchip,pins =
				<0 RK_PB6 12 &pcfg_pull_none>;
		};

		/omit-if-no-ref/
		pwm1m0_ch3_pins: pwm1m0-ch3-pins {
			rockchip,pins =
				<0 RK_PC0 12 &pcfg_pull_none>;
		};

		/omit-if-no-ref/
		pwm1m0_ch4_pins: pwm1m0-ch4-pins {
			rockchip,pins =
				<0 RK_PB7 12 &pcfg_pull_none>;
		};

		/omit-if-no-ref/
		pwm1m0_ch5_pins: pwm1m0-ch5-pins {
			rockchip,pins =
				<0 RK_PD2 12 &pcfg_pull_none>;
		};

		/omit-if-no-ref/
		pwm1m1_ch0_pins: pwm1m1-ch0-pins {
			rockchip,pins =
				<1 RK_PB4 12 &pcfg_pull_none>;
		};

		/omit-if-no-ref/
		pwm1m1_ch1_pins: pwm1m1-ch1-pins {
			rockchip,pins =
				<1 RK_PB5 12 &pcfg_pull_none>;
		};

		/omit-if-no-ref/
		pwm1m1_ch2_pins: pwm1m1-ch2-pins {
			rockchip,pins =
				<1 RK_PD6 12 &pcfg_pull_none>;
		};

		/omit-if-no-ref/
		pwm1m1_ch3_pins: pwm1m1-ch3-pins {
			rockchip,pins =
				<1 RK_PD2 12 &pcfg_pull_none>;
		};

		/omit-if-no-ref/
		pwm1m1_ch4_pins: pwm1m1-ch4-pins {
			rockchip,pins =
				<1 RK_PD3 12 &pcfg_pull_none>;
		};

		/omit-if-no-ref/
		pwm1m1_ch5_pins: pwm1m1-ch5-pins {
			rockchip,pins =
				<4 RK_PB0 12 &pcfg_pull_none>;
		};

		/omit-if-no-ref/
		pwm1m2_ch0_pins: pwm1m2-ch0-pins {
			rockchip,pins =
				<3 RK_PA4 12 &pcfg_pull_none>;
		};

		/omit-if-no-ref/
		pwm1m2_ch1_pins: pwm1m2-ch1-pins {
			rockchip,pins =
				<3 RK_PA5 12 &pcfg_pull_none>;
		};

		/omit-if-no-ref/
		pwm1m2_ch2_pins: pwm1m2-ch2-pins {
			rockchip,pins =
				<2 RK_PD0 12 &pcfg_pull_none>;
		};

		/omit-if-no-ref/
		pwm1m2_ch3_pins: pwm1m2-ch3-pins {
			rockchip,pins =
				<2 RK_PD2 12 &pcfg_pull_none>;
		};

		/omit-if-no-ref/
		pwm1m2_ch4_pins: pwm1m2-ch4-pins {
			rockchip,pins =
				<2 RK_PD3 12 &pcfg_pull_none>;
		};

		/omit-if-no-ref/
		pwm1m2_ch5_pins: pwm1m2-ch5-pins {
			rockchip,pins =
				<3 RK_PB5 12 &pcfg_pull_none>;
		};

		/omit-if-no-ref/
		pwm1m3_ch2_pins: pwm1m3-ch2-pins {
			rockchip,pins =
				<3 RK_PA6 12 &pcfg_pull_none>;
		};

		/omit-if-no-ref/
		pwm1m3_ch3_pins: pwm1m3-ch3-pins {
			rockchip,pins =
				<3 RK_PB1 12 &pcfg_pull_none>;
		};

		/omit-if-no-ref/
		pwm1m3_ch4_pins: pwm1m3-ch4-pins {
			rockchip,pins =
				<3 RK_PB4 12 &pcfg_pull_none>;
		};

		/omit-if-no-ref/
		pwm1m3_ch5_pins: pwm1m3-ch5-pins {
			rockchip,pins =
				<1 RK_PD4 12 &pcfg_pull_none>;
		};
	};

	pwm2 {
		/omit-if-no-ref/
		pwm2m0_ch0_pins: pwm2m0-ch0-pins {
			rockchip,pins =
				<0 RK_PD3 12 &pcfg_pull_none>;
		};

		/omit-if-no-ref/
		pwm2m0_ch1_pins: pwm2m0-ch1-pins {
			rockchip,pins =
				<1 RK_PB3 12 &pcfg_pull_none>;
		};

		/omit-if-no-ref/
		pwm2m0_ch2_pins: pwm2m0-ch2-pins {
			rockchip,pins =
				<2 RK_PA0 12 &pcfg_pull_none>;
		};

		/omit-if-no-ref/
		pwm2m0_ch3_pins: pwm2m0-ch3-pins {
			rockchip,pins =
				<2 RK_PA1 12 &pcfg_pull_none>;
		};

		/omit-if-no-ref/
		pwm2m0_ch4_pins: pwm2m0-ch4-pins {
			rockchip,pins =
				<2 RK_PA4 12 &pcfg_pull_none>;
		};

		/omit-if-no-ref/
		pwm2m0_ch5_pins: pwm2m0-ch5-pins {
			rockchip,pins =
				<2 RK_PB0 12 &pcfg_pull_none>;
		};

		/omit-if-no-ref/
		pwm2m0_ch6_pins: pwm2m0-ch6-pins {
			rockchip,pins =
				<2 RK_PB5 12 &pcfg_pull_none>;
		};

		/omit-if-no-ref/
		pwm2m0_ch7_pins: pwm2m0-ch7-pins {
			rockchip,pins =
				<2 RK_PC1 12 &pcfg_pull_none>;
		};

		/omit-if-no-ref/
		pwm2m1_ch0_pins: pwm2m1-ch0-pins {
			rockchip,pins =
				<4 RK_PB2 12 &pcfg_pull_none>;
		};

		/omit-if-no-ref/
		pwm2m1_ch1_pins: pwm2m1-ch1-pins {
			rockchip,pins =
				<4 RK_PB3 12 &pcfg_pull_none>;
		};

		/omit-if-no-ref/
		pwm2m1_ch2_pins: pwm2m1-ch2-pins {
			rockchip,pins =
				<4 RK_PB6 12 &pcfg_pull_none>;
		};

		/omit-if-no-ref/
		pwm2m1_ch3_pins: pwm2m1-ch3-pins {
			rockchip,pins =
				<4 RK_PB7 12 &pcfg_pull_none>;
		};

		/omit-if-no-ref/
		pwm2m1_ch4_pins: pwm2m1-ch4-pins {
			rockchip,pins =
				<2 RK_PB1 12 &pcfg_pull_none>;
		};

		/omit-if-no-ref/
		pwm2m1_ch5_pins: pwm2m1-ch5-pins {
			rockchip,pins =
				<4 RK_PB5 12 &pcfg_pull_none>;
		};

		/omit-if-no-ref/
		pwm2m1_ch6_pins: pwm2m1-ch6-pins {
			rockchip,pins =
				<4 RK_PB4 12 &pcfg_pull_none>;
		};

		/omit-if-no-ref/
		pwm2m1_ch7_pins: pwm2m1-ch7-pins {
			rockchip,pins =
				<1 RK_PB1 12 &pcfg_pull_none>;
		};

		/omit-if-no-ref/
		pwm2m2_ch0_pins: pwm2m2-ch0-pins {
			rockchip,pins =
				<3 RK_PC2 12 &pcfg_pull_none>;
		};

		/omit-if-no-ref/
		pwm2m2_ch1_pins: pwm2m2-ch1-pins {
			rockchip,pins =
				<3 RK_PC3 12 &pcfg_pull_none>;
		};

		/omit-if-no-ref/
		pwm2m2_ch2_pins: pwm2m2-ch2-pins {
			rockchip,pins =
				<2 RK_PD6 12 &pcfg_pull_none>;
		};

		/omit-if-no-ref/
		pwm2m2_ch3_pins: pwm2m2-ch3-pins {
			rockchip,pins =
				<2 RK_PD7 12 &pcfg_pull_none>;
		};

		/omit-if-no-ref/
		pwm2m2_ch4_pins: pwm2m2-ch4-pins {
			rockchip,pins =
				<2 RK_PC4 12 &pcfg_pull_none>;
		};

		/omit-if-no-ref/
		pwm2m2_ch5_pins: pwm2m2-ch5-pins {
			rockchip,pins =
				<2 RK_PC5 12 &pcfg_pull_none>;
		};

		/omit-if-no-ref/
		pwm2m2_ch6_pins: pwm2m2-ch6-pins {
			rockchip,pins =
				<3 RK_PD6 12 &pcfg_pull_none>;
		};

		/omit-if-no-ref/
		pwm2m2_ch7_pins: pwm2m2-ch7-pins {
			rockchip,pins =
				<3 RK_PD7 12 &pcfg_pull_none>;
		};

		/omit-if-no-ref/
		pwm2m3_ch2_pins: pwm2m3-ch2-pins {
			rockchip,pins =
				<3 RK_PC5 12 &pcfg_pull_none>;
		};

		/omit-if-no-ref/
		pwm2m3_ch3_pins: pwm2m3-ch3-pins {
			rockchip,pins =
				<3 RK_PD0 12 &pcfg_pull_none>;
		};

		/omit-if-no-ref/
		pwm2m3_ch4_pins: pwm2m3-ch4-pins {
			rockchip,pins =
				<3 RK_PD2 12 &pcfg_pull_none>;
		};

		/omit-if-no-ref/
		pwm2m3_ch5_pins: pwm2m3-ch5-pins {
			rockchip,pins =
				<3 RK_PD3 12 &pcfg_pull_none>;
		};
	};

	pwr {
		/omit-if-no-ref/
		pwr_ctrl1_pins: pwr-ctrl1-pins {
			rockchip,pins =
				<0 RK_PA3 9 &pcfg_pull_none>;
		};

		/omit-if-no-ref/
		pwr_ctrl2_pins: pwr-ctrl2-pins {
			rockchip,pins =
				<0 RK_PA4 9 &pcfg_pull_none>;
		};

		/omit-if-no-ref/
		pwr_ctrl3_pins: pwr-ctrl3-pins {
			rockchip,pins =
				<0 RK_PA5 9 &pcfg_pull_none>;
		};
	};

	ref_clk0 {
		/omit-if-no-ref/
		ref_clk0_clk0_pins: ref-clk0-clk0-pins {
			rockchip,pins =
				<0 RK_PA0 1 &pcfg_pull_none>;
		};
	};

	ref_clk1 {
		/omit-if-no-ref/
		ref_clk1_clk1_pins: ref-clk1-clk1-pins {
			rockchip,pins =
				<0 RK_PB4 1 &pcfg_pull_none>;
		};
	};

	ref_clk2 {
		/omit-if-no-ref/
		ref_clk2_clk2_pins: ref-clk2-clk2-pins {
			rockchip,pins =
				<0 RK_PB5 1 &pcfg_pull_none>;
		};
	};

	sai0 {
		/omit-if-no-ref/
		sai0m0_lrck_pins: sai0m0-lrck-pins {
			rockchip,pins =
				<2 RK_PD1 4 &pcfg_pull_none>;
		};

		/omit-if-no-ref/
		sai0m0_mclk_pins: sai0m0-mclk-pins {
			rockchip,pins =
				<2 RK_PC7 4 &pcfg_pull_none>;
		};

		/omit-if-no-ref/
		sai0m0_sclk_pins: sai0m0-sclk-pins {
			rockchip,pins =
				<2 RK_PD0 4 &pcfg_pull_none>;
		};

		/omit-if-no-ref/
		sai0m0_sdi0_pins: sai0m0-sdi0-pins {
			rockchip,pins =
				<2 RK_PD3 4 &pcfg_pull_none>;
		};

		/omit-if-no-ref/
		sai0m0_sdi1_pins: sai0m0-sdi1-pins {
			rockchip,pins =
				<2 RK_PC5 4 &pcfg_pull_none>;
		};

		/omit-if-no-ref/
		sai0m0_sdi2_pins: sai0m0-sdi2-pins {
			rockchip,pins =
				<2 RK_PC4 4 &pcfg_pull_none>;
		};

		/omit-if-no-ref/
		sai0m0_sdi3_pins: sai0m0-sdi3-pins {
			rockchip,pins =
				<2 RK_PD6 4 &pcfg_pull_none>;
		};

		/omit-if-no-ref/
		sai0m0_sdo0_pins: sai0m0-sdo0-pins {
			rockchip,pins =
				<2 RK_PD2 4 &pcfg_pull_none>;
		};

		/omit-if-no-ref/
		sai0m0_sdo1_pins: sai0m0-sdo1-pins {
			rockchip,pins =
				<2 RK_PC6 4 &pcfg_pull_none>;
		};

		/omit-if-no-ref/
		sai0m0_sdo2_pins: sai0m0-sdo2-pins {
			rockchip,pins =
				<2 RK_PD4 4 &pcfg_pull_none>;
		};

		/omit-if-no-ref/
		sai0m0_sdo3_pins: sai0m0-sdo3-pins {
			rockchip,pins =
				<2 RK_PD5 4 &pcfg_pull_none>;
		};

		/omit-if-no-ref/
		sai0m1_lrck_pins: sai0m1-lrck-pins {
			rockchip,pins =
				<0 RK_PC7 4 &pcfg_pull_none>;
		};

		/omit-if-no-ref/
		sai0m1_mclk_pins: sai0m1-mclk-pins {
			rockchip,pins =
				<0 RK_PC4 4 &pcfg_pull_none>;
		};

		/omit-if-no-ref/
		sai0m1_sclk_pins: sai0m1-sclk-pins {
			rockchip,pins =
				<0 RK_PC6 4 &pcfg_pull_none>;
		};

		/omit-if-no-ref/
		sai0m1_sdi0_pins: sai0m1-sdi0-pins {
			rockchip,pins =
				<0 RK_PD0 4 &pcfg_pull_none>;
		};

		/omit-if-no-ref/
		sai0m1_sdi1_pins: sai0m1-sdi1-pins {
			rockchip,pins =
				<0 RK_PD1 4 &pcfg_pull_none>;
		};

		/omit-if-no-ref/
		sai0m1_sdi2_pins: sai0m1-sdi2-pins {
			rockchip,pins =
				<0 RK_PD2 4 &pcfg_pull_none>;
		};

		/omit-if-no-ref/
		sai0m1_sdi3_pins: sai0m1-sdi3-pins {
			rockchip,pins =
				<0 RK_PD3 4 &pcfg_pull_none>;
		};

		/omit-if-no-ref/
		sai0m1_sdo0_pins: sai0m1-sdo0-pins {
			rockchip,pins =
				<0 RK_PC5 4 &pcfg_pull_none>;
		};

		/omit-if-no-ref/
		sai0m1_sdo1_pins: sai0m1-sdo1-pins {
			rockchip,pins =
				<0 RK_PD3 5 &pcfg_pull_none>;
		};

		/omit-if-no-ref/
		sai0m1_sdo2_pins: sai0m1-sdo2-pins {
			rockchip,pins =
				<0 RK_PD2 5 &pcfg_pull_none>;
		};

		/omit-if-no-ref/
		sai0m1_sdo3_pins: sai0m1-sdo3-pins {
			rockchip,pins =
				<0 RK_PD1 5 &pcfg_pull_none>;
		};

		/omit-if-no-ref/
		sai0m2_lrck_pins: sai0m2-lrck-pins {
			rockchip,pins =
				<2 RK_PB4 5 &pcfg_pull_none>;
		};

		/omit-if-no-ref/
		sai0m2_mclk_pins: sai0m2-mclk-pins {
			rockchip,pins =
				<2 RK_PB0 5 &pcfg_pull_none>;
		};

		/omit-if-no-ref/
		sai0m2_sclk_pins: sai0m2-sclk-pins {
			rockchip,pins =
				<2 RK_PB2 5 &pcfg_pull_none>;
		};

		/omit-if-no-ref/
		sai0m2_sdi0_pins: sai0m2-sdi0-pins {
			rockchip,pins =
				<2 RK_PB5 5 &pcfg_pull_none>;
		};

		/omit-if-no-ref/
		sai0m2_sdi1_pins: sai0m2-sdi1-pins {
			rockchip,pins =
				<2 RK_PB1 5 &pcfg_pull_none>;
		};

		/omit-if-no-ref/
		sai0m2_sdi2_pins: sai0m2-sdi2-pins {
			rockchip,pins =
				<2 RK_PB3 5 &pcfg_pull_none>;
		};

		/omit-if-no-ref/
		sai0m2_sdi3_pins: sai0m2-sdi3-pins {
			rockchip,pins =
				<2 RK_PC2 5 &pcfg_pull_none>;
		};

		/omit-if-no-ref/
		sai0m2_sdo0_pins: sai0m2-sdo0-pins {
			rockchip,pins =
				<2 RK_PC1 5 &pcfg_pull_none>;
		};
	};

	sai1 {
		/omit-if-no-ref/
		sai1m0_lrck_pins: sai1m0-lrck-pins {
			rockchip,pins =
				<2 RK_PB3 4 &pcfg_pull_none>;
		};

		/omit-if-no-ref/
		sai1m0_mclk_pins: sai1m0-mclk-pins {
			rockchip,pins =
				<2 RK_PB0 4 &pcfg_pull_none>;
		};

		/omit-if-no-ref/
		sai1m0_sclk_pins: sai1m0-sclk-pins {
			rockchip,pins =
				<2 RK_PB1 4 &pcfg_pull_none>;
		};

		/omit-if-no-ref/
		sai1m0_sdi0_pins: sai1m0-sdi0-pins {
			rockchip,pins =
				<2 RK_PC1 4 &pcfg_pull_none>;
		};

		/omit-if-no-ref/
		sai1m0_sdi1_pins: sai1m0-sdi1-pins {
			rockchip,pins =
				<2 RK_PC0 5 &pcfg_pull_none>;
		};

		/omit-if-no-ref/
		sai1m0_sdi2_pins: sai1m0-sdi2-pins {
			rockchip,pins =
				<2 RK_PB7 5 &pcfg_pull_none>;
		};

		/omit-if-no-ref/
		sai1m0_sdi3_pins: sai1m0-sdi3-pins {
			rockchip,pins =
				<2 RK_PB6 5 &pcfg_pull_none>;
		};

		/omit-if-no-ref/
		sai1m0_sdo0_pins: sai1m0-sdo0-pins {
			rockchip,pins =
				<2 RK_PB5 4 &pcfg_pull_none>;
		};

		/omit-if-no-ref/
		sai1m0_sdo1_pins: sai1m0-sdo1-pins {
			rockchip,pins =
				<2 RK_PB6 4 &pcfg_pull_none>;
		};

		/omit-if-no-ref/
		sai1m0_sdo2_pins: sai1m0-sdo2-pins {
			rockchip,pins =
				<2 RK_PB7 4 &pcfg_pull_none>;
		};

		/omit-if-no-ref/
		sai1m0_sdo3_pins: sai1m0-sdo3-pins {
			rockchip,pins =
				<2 RK_PC0 4 &pcfg_pull_none>;
		};

		/omit-if-no-ref/
		sai1m1_lrck_pins: sai1m1-lrck-pins {
			rockchip,pins =
				<4 RK_PA1 5 &pcfg_pull_none>;
		};

		/omit-if-no-ref/
		sai1m1_mclk_pins: sai1m1-mclk-pins {
			rockchip,pins =
				<3 RK_PB0 5 &pcfg_pull_none>;
		};

		/omit-if-no-ref/
		sai1m1_sclk_pins: sai1m1-sclk-pins {
			rockchip,pins =
				<3 RK_PA4 5 &pcfg_pull_none>;
		};

		/omit-if-no-ref/
		sai1m1_sdi0_pins: sai1m1-sdi0-pins {
			rockchip,pins =
				<3 RK_PB7 5 &pcfg_pull_none>;
		};

		/omit-if-no-ref/
		sai1m1_sdi1_pins: sai1m1-sdi1-pins {
			rockchip,pins =
				<3 RK_PD4 5 &pcfg_pull_none>;
		};

		/omit-if-no-ref/
		sai1m1_sdi2_pins: sai1m1-sdi2-pins {
			rockchip,pins =
				<3 RK_PD5 5 &pcfg_pull_none>;
		};

		/omit-if-no-ref/
		sai1m1_sdi3_pins: sai1m1-sdi3-pins {
			rockchip,pins =
				<3 RK_PD6 5 &pcfg_pull_none>;
		};

		/omit-if-no-ref/
		sai1m1_sdo0_pins: sai1m1-sdo0-pins {
			rockchip,pins =
				<4 RK_PA0 5 &pcfg_pull_none>;
		};

		/omit-if-no-ref/
		sai1m1_sdo1_pins: sai1m1-sdo1-pins {
			rockchip,pins =
				<3 RK_PD7 5 &pcfg_pull_none>;
		};

		/omit-if-no-ref/
		sai1m1_sdo2_pins: sai1m1-sdo2-pins {
			rockchip,pins =
				<3 RK_PC1 5 &pcfg_pull_none>;
		};

		/omit-if-no-ref/
		sai1m1_sdo3_pins: sai1m1-sdo3-pins {
			rockchip,pins =
				<3 RK_PC0 5 &pcfg_pull_none>;
		};
	};

	sai2 {
		/omit-if-no-ref/
		sai2m0_lrck_pins: sai2m0-lrck-pins {
			rockchip,pins =
				<1 RK_PD2 4 &pcfg_pull_none>;
		};

		/omit-if-no-ref/
		sai2m0_mclk_pins: sai2m0-mclk-pins {
			rockchip,pins =
				<1 RK_PD4 4 &pcfg_pull_none>;
		};

		/omit-if-no-ref/
		sai2m0_sclk_pins: sai2m0-sclk-pins {
			rockchip,pins =
				<1 RK_PD1 4 &pcfg_pull_none>;
		};

		/omit-if-no-ref/
		sai2m0_sdi_pins: sai2m0-sdi-pins {
			rockchip,pins =
				<1 RK_PD3 4 &pcfg_pull_none>;
		};

		/omit-if-no-ref/
		sai2m0_sdo_pins: sai2m0-sdo-pins {
			rockchip,pins =
				<1 RK_PD0 4 &pcfg_pull_none>;
		};

		/omit-if-no-ref/
		sai2m1_lrck_pins: sai2m1-lrck-pins {
			rockchip,pins =
				<3 RK_PC3 5 &pcfg_pull_none>;
		};

		/omit-if-no-ref/
		sai2m1_mclk_pins: sai2m1-mclk-pins {
			rockchip,pins =
				<3 RK_PC4 5 &pcfg_pull_none>;
		};

		/omit-if-no-ref/
		sai2m1_sclk_pins: sai2m1-sclk-pins {
			rockchip,pins =
				<3 RK_PC2 5 &pcfg_pull_none>;
		};

		/omit-if-no-ref/
		sai2m1_sdi_pins: sai2m1-sdi-pins {
			rockchip,pins =
				<3 RK_PD2 5 &pcfg_pull_none>;
		};

		/omit-if-no-ref/
		sai2m1_sdo_pins: sai2m1-sdo-pins {
			rockchip,pins =
				<3 RK_PD3 5 &pcfg_pull_none>;
		};
	};

	sai3 {
		/omit-if-no-ref/
		sai3m0_lrck_pins: sai3m0-lrck-pins {
			rockchip,pins =
				<1 RK_PA6 4 &pcfg_pull_none>;
		};

		/omit-if-no-ref/
		sai3m0_mclk_pins: sai3m0-mclk-pins {
			rockchip,pins =
				<1 RK_PA4 4 &pcfg_pull_none>;
		};

		/omit-if-no-ref/
		sai3m0_sclk_pins: sai3m0-sclk-pins {
			rockchip,pins =
				<1 RK_PA5 4 &pcfg_pull_none>;
		};

		/omit-if-no-ref/
		sai3m0_sdi_pins: sai3m0-sdi-pins {
			rockchip,pins =
				<1 RK_PA7 4 &pcfg_pull_none>;
		};

		/omit-if-no-ref/
		sai3m0_sdo_pins: sai3m0-sdo-pins {
			rockchip,pins =
				<1 RK_PB2 4 &pcfg_pull_none>;
		};

		/omit-if-no-ref/
		sai3m1_lrck_pins: sai3m1-lrck-pins {
			rockchip,pins =
				<2 RK_PA2 4 &pcfg_pull_none>;
		};

		/omit-if-no-ref/
		sai3m1_mclk_pins: sai3m1-mclk-pins {
			rockchip,pins =
				<2 RK_PA1 4 &pcfg_pull_none>;
		};

		/omit-if-no-ref/
		sai3m1_sclk_pins: sai3m1-sclk-pins {
			rockchip,pins =
				<2 RK_PA5 4 &pcfg_pull_none>;
		};

		/omit-if-no-ref/
		sai3m1_sdi_pins: sai3m1-sdi-pins {
			rockchip,pins =
				<2 RK_PA3 4 &pcfg_pull_none>;
		};

		/omit-if-no-ref/
		sai3m1_sdo_pins: sai3m1-sdo-pins {
			rockchip,pins =
				<2 RK_PA4 4 &pcfg_pull_none>;
		};

		/omit-if-no-ref/
		sai3m2_lrck_pins: sai3m2-lrck-pins {
			rockchip,pins =
				<4 RK_PB2 4 &pcfg_pull_none>;
		};

		/omit-if-no-ref/
		sai3m2_mclk_pins: sai3m2-mclk-pins {
			rockchip,pins =
				<4 RK_PB0 4 &pcfg_pull_none>;
		};

		/omit-if-no-ref/
		sai3m2_sclk_pins: sai3m2-sclk-pins {
			rockchip,pins =
				<4 RK_PB3 4 &pcfg_pull_none>;
		};

		/omit-if-no-ref/
		sai3m2_sdi_pins: sai3m2-sdi-pins {
			rockchip,pins =
				<4 RK_PB1 4 &pcfg_pull_none>;
		};

		/omit-if-no-ref/
		sai3m2_sdo_pins: sai3m2-sdo-pins {
			rockchip,pins =
				<4 RK_PB4 4 &pcfg_pull_none>;
		};
	};

	sai4 {
		/omit-if-no-ref/
		sai4m0_lrck_pins: sai4m0-lrck-pins {
			rockchip,pins =
				<1 RK_PA1 5 &pcfg_pull_none>;
		};

		/omit-if-no-ref/
		sai4m0_mclk_pins: sai4m0-mclk-pins {
			rockchip,pins =
				<1 RK_PA4 5 &pcfg_pull_none>;
		};

		/omit-if-no-ref/
		sai4m0_sclk_pins: sai4m0-sclk-pins {
			rockchip,pins =
				<1 RK_PA0 5 &pcfg_pull_none>;
		};

		/omit-if-no-ref/
		sai4m0_sdi0_pins: sai4m0-sdi0-pins {
			rockchip,pins =
				<1 RK_PB2 5 &pcfg_pull_none>;
		};

		/omit-if-no-ref/
		sai4m0_sdi1_pins: sai4m0-sdi1-pins {
			rockchip,pins =
				<1 RK_PB1 4 &pcfg_pull_none>;
		};

		/omit-if-no-ref/
		sai4m0_sdi2_pins: sai4m0-sdi2-pins {
			rockchip,pins =
				<1 RK_PA3 4 &pcfg_pull_none>;
		};

		/omit-if-no-ref/
		sai4m0_sdi3_pins: sai4m0-sdi3-pins {
			rockchip,pins =
				<1 RK_PA2 4 &pcfg_pull_none>;
		};

		/omit-if-no-ref/
		sai4m0_sdo0_pins: sai4m0-sdo0-pins {
			rockchip,pins =
				<1 RK_PA7 5 &pcfg_pull_none>;
		};

		/omit-if-no-ref/
		sai4m0_sdo1_pins: sai4m0-sdo1-pins {
			rockchip,pins =
				<1 RK_PA2 5 &pcfg_pull_none>;
		};

		/omit-if-no-ref/
		sai4m0_sdo2_pins: sai4m0-sdo2-pins {
			rockchip,pins =
				<1 RK_PA3 5 &pcfg_pull_none>;
		};

		/omit-if-no-ref/
		sai4m0_sdo3_pins: sai4m0-sdo3-pins {
			rockchip,pins =
				<1 RK_PB1 5 &pcfg_pull_none>;
		};

		/omit-if-no-ref/
		sai4m1_lrck_pins: sai4m1-lrck-pins {
			rockchip,pins =
				<1 RK_PB5 4 &pcfg_pull_none>;
		};

		/omit-if-no-ref/
		sai4m1_mclk_pins: sai4m1-mclk-pins {
			rockchip,pins =
				<1 RK_PB4 4 &pcfg_pull_none>;
		};

		/omit-if-no-ref/
		sai4m1_sclk_pins: sai4m1-sclk-pins {
			rockchip,pins =
				<1 RK_PC0 4 &pcfg_pull_none>;
		};

		/omit-if-no-ref/
		sai4m1_sdi0_pins: sai4m1-sdi0-pins {
			rockchip,pins =
				<1 RK_PB6 4 &pcfg_pull_none>;
		};

		/omit-if-no-ref/
		sai4m1_sdo0_pins: sai4m1-sdo0-pins {
			rockchip,pins =
				<1 RK_PB7 4 &pcfg_pull_none>;
		};
	};

	sata0 {
		/omit-if-no-ref/
		sata0m0_sata_pins: sata0m0-sata-pins {
			rockchip,pins =
				<1 RK_PC3 14 &pcfg_pull_none>,
				<1 RK_PC2 14 &pcfg_pull_none>,
				<1 RK_PD6 14 &pcfg_pull_none>;
		};

		/omit-if-no-ref/
		sata0m1_sata_pins: sata0m1-sata-pins {
			rockchip,pins =
				<3 RK_PD0 14 &pcfg_pull_none>,
				<3 RK_PC7 14 &pcfg_pull_none>,
				<3 RK_PC4 14 &pcfg_pull_none>;
		};
	};

	sata1 {
		/omit-if-no-ref/
		sata1m0_sata_pins: sata1m0-sata-pins {
			rockchip,pins =
				<1 RK_PD2 14 &pcfg_pull_none>,
				<1 RK_PD1 14 &pcfg_pull_none>,
				<1 RK_PD3 14 &pcfg_pull_none>;
		};

		/omit-if-no-ref/
		sata1m1_sata_pins: sata1m1-sata-pins {
			rockchip,pins =
				<4 RK_PA1 14 &pcfg_pull_none>,
				<4 RK_PA0 14 &pcfg_pull_none>,
				<3 RK_PD7 14 &pcfg_pull_none>;
		};
	};

	sata30_port0 {
		/omit-if-no-ref/
		sata30_port0m0_port0_pins: sata30-port0m0-port0-pins {
			rockchip,pins =
				<2 RK_PD2 7 &pcfg_pull_none>;
		};

		/omit-if-no-ref/
		sata30_port0m1_port0_pins: sata30-port0m1-port0-pins {
			rockchip,pins =
				<4 RK_PB5 6 &pcfg_pull_none>;
		};
	};

	sata30_port1 {
		/omit-if-no-ref/
		sata30_port1m0_port1_pins: sata30-port1m0-port1-pins {
			rockchip,pins =
				<2 RK_PD1 7 &pcfg_pull_none>;
		};

		/omit-if-no-ref/
		sata30_port1m1_port1_pins: sata30-port1m1-port1-pins {
			rockchip,pins =
				<4 RK_PB6 6 &pcfg_pull_none>;
		};
	};

	sdmmc0 {
		/omit-if-no-ref/
		sdmmc0m0_bus4_pins: sdmmc0m0-bus4-pins {
			rockchip,pins =
				<2 RK_PA0 2 &pcfg_pull_up_drv_level_2>,
				<2 RK_PA1 2 &pcfg_pull_up_drv_level_2>,
				<2 RK_PA2 2 &pcfg_pull_up_drv_level_2>,
				<2 RK_PA3 2 &pcfg_pull_up_drv_level_2>;
		};

		/omit-if-no-ref/
		sdmmc0m0_clk_pins: sdmmc0m0-clk-pins {
			rockchip,pins =
				<2 RK_PA5 2 &pcfg_pull_up_drv_level_2>;
		};

		/omit-if-no-ref/
		sdmmc0m0_cmd_pins: sdmmc0m0-cmd-pins {
			rockchip,pins =
				<2 RK_PA4 2 &pcfg_pull_up_drv_level_2>;
		};

		/omit-if-no-ref/
		sdmmc0m0_det_pins: sdmmc0m0-det-pins {
			rockchip,pins =
				<0 RK_PA7 1 &pcfg_pull_up>;
		};

		/omit-if-no-ref/
		sdmmc0m1_bus4_pins: sdmmc0m1-bus4-pins {
			rockchip,pins =
				<2 RK_PC4 3 &pcfg_pull_up_drv_level_2>,
				<2 RK_PC5 3 &pcfg_pull_up_drv_level_2>,
				<2 RK_PC6 3 &pcfg_pull_up_drv_level_2>,
				<2 RK_PC7 3 &pcfg_pull_up_drv_level_2>;
		};

		/omit-if-no-ref/
		sdmmc0m1_clk_pins: sdmmc0m1-clk-pins {
			rockchip,pins =
				<2 RK_PD1 3 &pcfg_pull_up_drv_level_2>;
		};

		/omit-if-no-ref/
		sdmmc0m1_cmd_pins: sdmmc0m1-cmd-pins {
			rockchip,pins =
				<2 RK_PD0 3 &pcfg_pull_up_drv_level_2>;
		};

		/omit-if-no-ref/
		sdmmc0m1_det_pins: sdmmc0m1-det-pins {
			rockchip,pins =
				<2 RK_PD3 3 &pcfg_pull_up>;
		};

		/omit-if-no-ref/
		sdmmc0m1_pwren_pins: sdmmc0m1-pwren-pins {
			rockchip,pins =
				<2 RK_PD2 3 &pcfg_pull_none>;
		};

		/omit-if-no-ref/
		sdmmc0_pwren_pins: sdmmc0-pwren-pins {
			rockchip,pins =
				<0 RK_PB6 1 &pcfg_pull_none>;
		};
	};

	sdmmc1 {
		/omit-if-no-ref/
		sdmmc1m0_det_pins: sdmmc1m0-det-pins {
			rockchip,pins =
				<1 RK_PC3 2 &pcfg_pull_up>;
		};

		/omit-if-no-ref/
		sdmmc1m1_det_pins: sdmmc1m1-det-pins {
			rockchip,pins =
				<0 RK_PB6 2 &pcfg_pull_up>;
		};

		/omit-if-no-ref/
		sdmmc1_bus4_pins: sdmmc1-bus4-pins {
			rockchip,pins =
				<1 RK_PB4 2 &pcfg_pull_up_drv_level_2>,
				<1 RK_PB5 2 &pcfg_pull_up_drv_level_2>,
				<1 RK_PB6 2 &pcfg_pull_up_drv_level_2>,
				<1 RK_PB7 2 &pcfg_pull_up_drv_level_2>;
		};

		/omit-if-no-ref/
		sdmmc1_clk_pins: sdmmc1-clk-pins {
			rockchip,pins =
				<1 RK_PC1 2 &pcfg_pull_up_drv_level_2>;
		};

		/omit-if-no-ref/
		sdmmc1_cmd_pins: sdmmc1-cmd-pins {
			rockchip,pins =
				<1 RK_PC0 2 &pcfg_pull_up_drv_level_2>;
		};

		/omit-if-no-ref/
		sdmmc1_pwren_pins: sdmmc1-pwren-pins {
			rockchip,pins =
				<1 RK_PC2 2 &pcfg_pull_none>;
		};
	};

	spdif {
		/omit-if-no-ref/
		spdifm0_rx0_pins: spdifm0-rx0-pins {
			rockchip,pins =
				<2 RK_PC2 6 &pcfg_pull_none>;
		};

		/omit-if-no-ref/
		spdifm0_tx0_pins: spdifm0-tx0-pins {
			rockchip,pins =
				<2 RK_PC3 6 &pcfg_pull_none>;
		};

		/omit-if-no-ref/
		spdifm0_tx1_pins: spdifm0-tx1-pins {
			rockchip,pins =
				<2 RK_PB4 4 &pcfg_pull_none>;
		};

		/omit-if-no-ref/
		spdifm1_rx0_pins: spdifm1-rx0-pins {
			rockchip,pins =
				<1 RK_PD4 6 &pcfg_pull_none>;
		};

		/omit-if-no-ref/
		spdifm1_tx0_pins: spdifm1-tx0-pins {
			rockchip,pins =
				<1 RK_PD5 6 &pcfg_pull_none>;
		};

		/omit-if-no-ref/
		spdifm1_tx1_pins: spdifm1-tx1-pins {
			rockchip,pins =
				<1 RK_PD6 6 &pcfg_pull_none>;
		};

		/omit-if-no-ref/
		spdifm2_rx0_pins: spdifm2-rx0-pins {
			rockchip,pins =
				<2 RK_PD6 5 &pcfg_pull_none>;
		};

		/omit-if-no-ref/
		spdifm2_tx0_pins: spdifm2-tx0-pins {
			rockchip,pins =
				<2 RK_PD7 5 &pcfg_pull_none>;
		};

		/omit-if-no-ref/
		spdifm2_tx1_pins: spdifm2-tx1-pins {
			rockchip,pins =
				<2 RK_PD5 5 &pcfg_pull_none>;
		};

		/omit-if-no-ref/
		spdifm3_rx0_pins: spdifm3-rx0-pins {
			rockchip,pins =
				<3 RK_PB4 5 &pcfg_pull_none>;
		};

		/omit-if-no-ref/
		spdifm3_tx0_pins: spdifm3-tx0-pins {
			rockchip,pins =
				<3 RK_PB5 5 &pcfg_pull_none>;
		};

		/omit-if-no-ref/
		spdifm3_tx1_pins: spdifm3-tx1-pins {
			rockchip,pins =
				<3 RK_PB6 5 &pcfg_pull_none>;
		};

		/omit-if-no-ref/
		spdifm4_rx0_pins: spdifm4-rx0-pins {
			rockchip,pins =
				<4 RK_PA0 6 &pcfg_pull_none>;
		};

		/omit-if-no-ref/
		spdifm4_tx0_pins: spdifm4-tx0-pins {
			rockchip,pins =
				<4 RK_PA1 6 &pcfg_pull_none>;
		};
	};

	spdif_rx0 {
		/omit-if-no-ref/
		spdif_rx0_rx0_pins: spdif-rx0-rx0-pins {
			rockchip,pins =
				<2 RK_PB7 7 &pcfg_pull_none>;
		};
	};

	spdif_rx1 {
		/omit-if-no-ref/
		spdif_rx1_rx1_pins: spdif-rx1-rx1-pins {
			rockchip,pins =
				<1 RK_PD6 7 &pcfg_pull_none>;
		};
	};

	spi0 {
		/omit-if-no-ref/
		spi0m0_pins: spi0m0-pins {
			rockchip,pins =
				<0 RK_PC7 10 &pcfg_pull_none>,
				<0 RK_PD1 10 &pcfg_pull_none>,
				<0 RK_PD0 10 &pcfg_pull_none>;
		};

		/omit-if-no-ref/
		spi0m0_csn0_pins: spi0m0-csn0-pins {
			rockchip,pins =
				<0 RK_PC6 10 &pcfg_pull_none>;
		};

		/omit-if-no-ref/
		spi0m0_csn1_pins: spi0m0-csn1-pins {
			rockchip,pins =
				<0 RK_PC3 10 &pcfg_pull_none>;
		};

		/omit-if-no-ref/
		spi0m1_pins: spi0m1-pins {
			rockchip,pins =
				<2 RK_PA5 10 &pcfg_pull_none>,
				<2 RK_PA1 10 &pcfg_pull_none>,
				<2 RK_PA0 10 &pcfg_pull_none>;
		};

		/omit-if-no-ref/
		spi0m1_csn0_pins: spi0m1-csn0-pins {
			rockchip,pins =
				<2 RK_PA4 10 &pcfg_pull_none>;
		};

		/omit-if-no-ref/
		spi0m1_csn1_pins: spi0m1-csn1-pins {
			rockchip,pins =
				<2 RK_PA2 10 &pcfg_pull_none>;
		};

		/omit-if-no-ref/
		spi0m2_pins: spi0m2-pins {
			rockchip,pins =
				<1 RK_PA7 10 &pcfg_pull_none>,
				<1 RK_PA6 10 &pcfg_pull_none>,
				<1 RK_PA5 10 &pcfg_pull_none>;
		};

		/omit-if-no-ref/
		spi0m2_csn0_pins: spi0m2-csn0-pins {
			rockchip,pins =
				<1 RK_PA4 10 &pcfg_pull_none>;
		};

		/omit-if-no-ref/
		spi0m2_csn1_pins: spi0m2-csn1-pins {
			rockchip,pins =
				<1 RK_PB2 10 &pcfg_pull_none>;
		};
	};

	spi1 {
		/omit-if-no-ref/
		spi1m0_pins: spi1m0-pins {
			rockchip,pins =
				<1 RK_PB4 10 &pcfg_pull_none>,
				<1 RK_PB6 10 &pcfg_pull_none>,
				<1 RK_PB5 10 &pcfg_pull_none>;
		};

		/omit-if-no-ref/
		spi1m0_csn0_pins: spi1m0-csn0-pins {
			rockchip,pins =
				<1 RK_PB7 10 &pcfg_pull_none>;
		};

		/omit-if-no-ref/
		spi1m0_csn1_pins: spi1m0-csn1-pins {
			rockchip,pins =
				<1 RK_PC0 10 &pcfg_pull_none>;
		};

		/omit-if-no-ref/
		spi1m1_pins: spi1m1-pins {
			rockchip,pins =
				<2 RK_PD3 10 &pcfg_pull_none>,
				<2 RK_PD1 10 &pcfg_pull_none>,
				<2 RK_PD0 10 &pcfg_pull_none>;
		};

		/omit-if-no-ref/
		spi1m1_csn0_pins: spi1m1-csn0-pins {
			rockchip,pins =
				<2 RK_PD2 10 &pcfg_pull_none>;
		};

		/omit-if-no-ref/
		spi1m1_csn1_pins: spi1m1-csn1-pins {
			rockchip,pins =
				<2 RK_PC7 10 &pcfg_pull_none>;
		};

		/omit-if-no-ref/
		spi1m2_pins: spi1m2-pins {
			rockchip,pins =
				<3 RK_PC7 10 &pcfg_pull_none>,
				<3 RK_PC5 10 &pcfg_pull_none>,
				<3 RK_PC6 10 &pcfg_pull_none>;
		};

		/omit-if-no-ref/
		spi1m2_csn0_pins: spi1m2-csn0-pins {
			rockchip,pins =
				<3 RK_PD0 10 &pcfg_pull_none>;
		};

		/omit-if-no-ref/
		spi1m2_csn1_pins: spi1m2-csn1-pins {
			rockchip,pins =
				<4 RK_PA0 10 &pcfg_pull_none>;
		};
	};

	spi2 {
		/omit-if-no-ref/
		spi2m0_pins: spi2m0-pins {
			rockchip,pins =
				<0 RK_PB2 10 &pcfg_pull_none>,
				<0 RK_PB1 10 &pcfg_pull_none>,
				<0 RK_PB3 10 &pcfg_pull_none>;
		};

		/omit-if-no-ref/
		spi2m0_csn0_pins: spi2m0-csn0-pins {
			rockchip,pins =
				<0 RK_PB0 10 &pcfg_pull_none>;
		};

		/omit-if-no-ref/
		spi2m0_csn1_pins: spi2m0-csn1-pins {
			rockchip,pins =
				<0 RK_PA7 10 &pcfg_pull_none>;
		};

		/omit-if-no-ref/
		spi2m1_pins: spi2m1-pins {
			rockchip,pins =
				<1 RK_PD5 10 &pcfg_pull_none>,
				<1 RK_PC5 10 &pcfg_pull_none>,
				<1 RK_PC4 10 &pcfg_pull_none>;
		};

		/omit-if-no-ref/
		spi2m1_csn0_pins: spi2m1-csn0-pins {
			rockchip,pins =
				<1 RK_PC6 10 &pcfg_pull_none>;
		};

		/omit-if-no-ref/
		spi2m1_csn1_pins: spi2m1-csn1-pins {
			rockchip,pins =
				<1 RK_PC7 10 &pcfg_pull_none>;
		};

		/omit-if-no-ref/
		spi2m2_pins: spi2m2-pins {
			rockchip,pins =
				<3 RK_PA4 10 &pcfg_pull_none>,
				<3 RK_PC1 10 &pcfg_pull_none>,
				<3 RK_PB0 10 &pcfg_pull_none>;
		};

		/omit-if-no-ref/
		spi2m2_csn0_pins: spi2m2-csn0-pins {
			rockchip,pins =
				<3 RK_PC4 10 &pcfg_pull_none>;
		};

		/omit-if-no-ref/
		spi2m2_csn1_pins: spi2m2-csn1-pins {
			rockchip,pins =
				<3 RK_PA5 10 &pcfg_pull_none>;
		};
	};

	spi3 {
		/omit-if-no-ref/
		spi3m0_pins: spi3m0-pins {
			rockchip,pins =
				<2 RK_PD4 10 &pcfg_pull_none>,
				<2 RK_PD6 10 &pcfg_pull_none>,
				<2 RK_PD5 10 &pcfg_pull_none>;
		};

		/omit-if-no-ref/
		spi3m0_csn0_pins: spi3m0-csn0-pins {
			rockchip,pins =
				<2 RK_PD7 10 &pcfg_pull_none>;
		};

		/omit-if-no-ref/
		spi3m0_csn1_pins: spi3m0-csn1-pins {
			rockchip,pins =
				<2 RK_PC6 10 &pcfg_pull_none>;
		};

		/omit-if-no-ref/
		spi3m1_pins: spi3m1-pins {
			rockchip,pins =
				<3 RK_PD4 10 &pcfg_pull_none>,
				<3 RK_PD5 10 &pcfg_pull_none>,
				<3 RK_PD6 10 &pcfg_pull_none>;
		};

		/omit-if-no-ref/
		spi3m1_csn0_pins: spi3m1-csn0-pins {
			rockchip,pins =
				<3 RK_PB6 10 &pcfg_pull_none>;
		};

		/omit-if-no-ref/
		spi3m1_csn1_pins: spi3m1-csn1-pins {
			rockchip,pins =
				<3 RK_PD3 10 &pcfg_pull_none>;
		};

		/omit-if-no-ref/
		spi3m2_pins: spi3m2-pins {
			rockchip,pins =
				<2 RK_PB5 10 &pcfg_pull_none>,
				<2 RK_PB4 10 &pcfg_pull_none>,
				<2 RK_PB2 10 &pcfg_pull_none>;
		};

		/omit-if-no-ref/
		spi3m2_csn0_pins: spi3m2-csn0-pins {
			rockchip,pins =
				<2 RK_PB1 10 &pcfg_pull_none>;
		};

		/omit-if-no-ref/
		spi3m2_csn1_pins: spi3m2-csn1-pins {
			rockchip,pins =
				<2 RK_PC1 11 &pcfg_pull_none>;
		};
	};

	spi4 {
		/omit-if-no-ref/
		spi4m0_pins: spi4m0-pins {
			rockchip,pins =
				<4 RK_PB7 10 &pcfg_pull_none>,
				<4 RK_PB6 10 &pcfg_pull_none>,
				<4 RK_PB5 10 &pcfg_pull_none>;
		};

		/omit-if-no-ref/
		spi4m0_csn0_pins: spi4m0-csn0-pins {
			rockchip,pins =
				<4 RK_PB4 10 &pcfg_pull_none>;
		};

		/omit-if-no-ref/
		spi4m0_csn1_pins: spi4m0-csn1-pins {
			rockchip,pins =
				<4 RK_PB0 10 &pcfg_pull_none>;
		};

		/omit-if-no-ref/
		spi4m1_pins: spi4m1-pins {
			rockchip,pins =
				<3 RK_PD1 10 &pcfg_pull_none>,
				<3 RK_PC2 10 &pcfg_pull_none>,
				<3 RK_PC3 10 &pcfg_pull_none>;
		};

		/omit-if-no-ref/
		spi4m1_csn0_pins: spi4m1-csn0-pins {
			rockchip,pins =
				<3 RK_PB1 10 &pcfg_pull_none>;
		};

		/omit-if-no-ref/
		spi4m1_csn1_pins: spi4m1-csn1-pins {
			rockchip,pins =
				<3 RK_PD2 10 &pcfg_pull_none>;
		};

		/omit-if-no-ref/
		spi4m2_pins: spi4m2-pins {
			rockchip,pins =
				<2 RK_PB6 10 &pcfg_pull_none>,
				<2 RK_PC0 10 &pcfg_pull_none>,
				<2 RK_PB7 10 &pcfg_pull_none>;
		};

		/omit-if-no-ref/
		spi4m2_csn0_pins: spi4m2-csn0-pins {
			rockchip,pins =
				<2 RK_PC1 10 &pcfg_pull_none>;
		};

		/omit-if-no-ref/
		spi4m2_csn1_pins: spi4m2-csn1-pins {
			rockchip,pins =
				<2 RK_PB3 10 &pcfg_pull_none>;
		};
	};

	tsadc {
		/omit-if-no-ref/
		tsadcm0_pins: tsadcm0-pins {
			rockchip,pins =
				<0 RK_PA1 9 &pcfg_pull_none>;
		};

		/omit-if-no-ref/
		tsadcm1_pins: tsadcm1-pins {
			rockchip,pins =
				<0 RK_PA3 10 &pcfg_pull_none>;
		};
	};

	tsadc_ctrl {
		/omit-if-no-ref/
		tsadc_ctrl_pins: tsadc-ctrl-pins {
			rockchip,pins =
				<0 RK_PA1 10 &pcfg_pull_none>;
		};
	};

	uart0 {
		/omit-if-no-ref/
		uart0m0_xfer_pins: uart0m0-xfer-pins {
			rockchip,pins =
				<0 RK_PD5 9 &pcfg_pull_up>,
				<0 RK_PD4 9 &pcfg_pull_up>;
		};

		/omit-if-no-ref/
		uart0m1_xfer_pins: uart0m1-xfer-pins {
			rockchip,pins =
				<2 RK_PA0 9 &pcfg_pull_up>,
				<2 RK_PA1 9 &pcfg_pull_up>;
		};
	};

	uart1 {
		/omit-if-no-ref/
		uart1m0_xfer_pins: uart1m0-xfer-pins {
			rockchip,pins =
				<0 RK_PC0 9 &pcfg_pull_up>,
				<0 RK_PB7 9 &pcfg_pull_up>;
		};

		/omit-if-no-ref/
		uart1m0_ctsn_pins: uart1m0-ctsn-pins {
			rockchip,pins =
				<0 RK_PD2 9 &pcfg_pull_none>;
		};

		/omit-if-no-ref/
		uart1m0_rtsn_pins: uart1m0-rtsn-pins {
			rockchip,pins =
				<0 RK_PD3 9 &pcfg_pull_none>;
		};

		/omit-if-no-ref/
		uart1m1_xfer_pins: uart1m1-xfer-pins {
			rockchip,pins =
				<2 RK_PD3 9 &pcfg_pull_up>,
				<2 RK_PD2 9 &pcfg_pull_up>;
		};

		/omit-if-no-ref/
		uart1m1_ctsn_pins: uart1m1-ctsn-pins {
			rockchip,pins =
				<2 RK_PD0 9 &pcfg_pull_none>;
		};

		/omit-if-no-ref/
		uart1m1_rtsn_pins: uart1m1-rtsn-pins {
			rockchip,pins =
				<2 RK_PD1 9 &pcfg_pull_none>;
		};

		/omit-if-no-ref/
		uart1m2_xfer_pins: uart1m2-xfer-pins {
			rockchip,pins =
				<3 RK_PA6 9 &pcfg_pull_up>,
				<3 RK_PA7 9 &pcfg_pull_up>;
		};

		/omit-if-no-ref/
		uart1m2_ctsn_pins: uart1m2-ctsn-pins {
			rockchip,pins =
				<3 RK_PA4 9 &pcfg_pull_none>;
		};

		/omit-if-no-ref/
		uart1m2_rtsn_pins: uart1m2-rtsn-pins {
			rockchip,pins =
				<3 RK_PA5 9 &pcfg_pull_none>;
		};
	};

	uart2 {
		/omit-if-no-ref/
		uart2m0_xfer_pins: uart2m0-xfer-pins {
			rockchip,pins =
				<1 RK_PC7 9 &pcfg_pull_up>,
				<1 RK_PC6 9 &pcfg_pull_up>;
		};

		/omit-if-no-ref/
		uart2m0_ctsn_pins: uart2m0-ctsn-pins {
			rockchip,pins =
				<1 RK_PC5 11 &pcfg_pull_none>;
		};

		/omit-if-no-ref/
		uart2m0_rtsn_pins: uart2m0-rtsn-pins {
			rockchip,pins =
				<1 RK_PC4 11 &pcfg_pull_none>;
		};

		/omit-if-no-ref/
		uart2m1_xfer_pins: uart2m1-xfer-pins {
			rockchip,pins =
				<2 RK_PB4 9 &pcfg_pull_up>,
				<2 RK_PB5 9 &pcfg_pull_up>;
		};

		/omit-if-no-ref/
		uart2m1_ctsn_pins: uart2m1-ctsn-pins {
			rockchip,pins =
				<2 RK_PB7 12 &pcfg_pull_none>;
		};

		/omit-if-no-ref/
		uart2m1_rtsn_pins: uart2m1-rtsn-pins {
			rockchip,pins =
				<2 RK_PB6 12 &pcfg_pull_none>;
		};

		/omit-if-no-ref/
		uart2m2_xfer_pins: uart2m2-xfer-pins {
			rockchip,pins =
				<3 RK_PB7 9 &pcfg_pull_up>,
				<3 RK_PC0 9 &pcfg_pull_up>;
		};

		/omit-if-no-ref/
		uart2m2_ctsn_pins: uart2m2-ctsn-pins {
			rockchip,pins =
				<3 RK_PD3 9 &pcfg_pull_none>;
		};

		/omit-if-no-ref/
		uart2m2_rtsn_pins: uart2m2-rtsn-pins {
			rockchip,pins =
				<3 RK_PD2 9 &pcfg_pull_none>;
		};
	};

	uart3 {
		/omit-if-no-ref/
		uart3m0_xfer_pins: uart3m0-xfer-pins {
			rockchip,pins =
				<2 RK_PD5 9 &pcfg_pull_up>,
				<2 RK_PD4 9 &pcfg_pull_up>;
		};

		/omit-if-no-ref/
		uart3m0_ctsn_pins: uart3m0-ctsn-pins {
			rockchip,pins =
				<2 RK_PD6 9 &pcfg_pull_none>;
		};

		/omit-if-no-ref/
		uart3m0_rtsn_pins: uart3m0-rtsn-pins {
			rockchip,pins =
				<2 RK_PD7 9 &pcfg_pull_none>;
		};

		/omit-if-no-ref/
		uart3m1_xfer_pins: uart3m1-xfer-pins {
			rockchip,pins =
				<3 RK_PB2 9 &pcfg_pull_up>,
				<3 RK_PB3 9 &pcfg_pull_up>;
		};

		/omit-if-no-ref/
		uart3m1_ctsn_pins: uart3m1-ctsn-pins {
			rockchip,pins =
				<3 RK_PB5 9 &pcfg_pull_none>;
		};

		/omit-if-no-ref/
		uart3m1_rtsn_pins: uart3m1-rtsn-pins {
			rockchip,pins =
				<3 RK_PB4 9 &pcfg_pull_none>;
		};

		/omit-if-no-ref/
		uart3m2_xfer_pins: uart3m2-xfer-pins {
			rockchip,pins =
				<1 RK_PC1 9 &pcfg_pull_up>,
				<1 RK_PC0 9 &pcfg_pull_up>;
		};

		/omit-if-no-ref/
		uart3m2_ctsn_pins: uart3m2-ctsn-pins {
			rockchip,pins =
				<1 RK_PB6 9 &pcfg_pull_none>;
		};

		/omit-if-no-ref/
		uart3m2_rtsn_pins: uart3m2-rtsn-pins {
			rockchip,pins =
				<1 RK_PB7 9 &pcfg_pull_none>;
		};
	};

	uart4 {
		/omit-if-no-ref/
		uart4m0_xfer_pins: uart4m0-xfer-pins {
			rockchip,pins =
				<3 RK_PC1 9 &pcfg_pull_up>,
				<3 RK_PC4 9 &pcfg_pull_up>;
		};

		/omit-if-no-ref/
		uart4m0_ctsn_pins: uart4m0-ctsn-pins {
			rockchip,pins =
				<3 RK_PC3 9 &pcfg_pull_none>;
		};

		/omit-if-no-ref/
		uart4m0_rtsn_pins: uart4m0-rtsn-pins {
			rockchip,pins =
				<3 RK_PC2 9 &pcfg_pull_none>;
		};

		/omit-if-no-ref/
		uart4m1_xfer_pins: uart4m1-xfer-pins {
			rockchip,pins =
				<1 RK_PC5 9 &pcfg_pull_up>,
				<1 RK_PC4 9 &pcfg_pull_up>;
		};

		/omit-if-no-ref/
		uart4m1_ctsn_pins: uart4m1-ctsn-pins {
			rockchip,pins =
				<1 RK_PC3 9 &pcfg_pull_none>;
		};

		/omit-if-no-ref/
		uart4m1_rtsn_pins: uart4m1-rtsn-pins {
			rockchip,pins =
				<1 RK_PC2 9 &pcfg_pull_none>;
		};

		/omit-if-no-ref/
		uart4m2_xfer_pins: uart4m2-xfer-pins {
			rockchip,pins =
				<0 RK_PB5 9 &pcfg_pull_up>,
				<0 RK_PB4 9 &pcfg_pull_up>;
		};
	};

	uart5 {
		/omit-if-no-ref/
		uart5m0_xfer_pins: uart5m0-xfer-pins {
			rockchip,pins =
				<3 RK_PD4 9 &pcfg_pull_up>,
				<3 RK_PD5 9 &pcfg_pull_up>;
		};

		/omit-if-no-ref/
		uart5m0_ctsn_pins: uart5m0-ctsn-pins {
			rockchip,pins =
				<3 RK_PD6 9 &pcfg_pull_none>;
		};

		/omit-if-no-ref/
		uart5m0_rtsn_pins: uart5m0-rtsn-pins {
			rockchip,pins =
				<3 RK_PD7 9 &pcfg_pull_none>;
		};

		/omit-if-no-ref/
		uart5m1_xfer_pins: uart5m1-xfer-pins {
			rockchip,pins =
				<2 RK_PC2 9 &pcfg_pull_up>,
				<2 RK_PC3 9 &pcfg_pull_up>;
		};

		/omit-if-no-ref/
		uart5m1_ctsn_pins: uart5m1-ctsn-pins {
			rockchip,pins =
				<2 RK_PC1 9 &pcfg_pull_none>;
		};

		/omit-if-no-ref/
		uart5m1_rtsn_pins: uart5m1-rtsn-pins {
			rockchip,pins =
				<2 RK_PC0 9 &pcfg_pull_none>;
		};

		/omit-if-no-ref/
		uart5m2_xfer_pins: uart5m2-xfer-pins {
			rockchip,pins =
				<2 RK_PA4 9 &pcfg_pull_up>,
				<2 RK_PA5 9 &pcfg_pull_up>;
		};

		/omit-if-no-ref/
		uart5m2_ctsn_pins: uart5m2-ctsn-pins {
			rockchip,pins =
				<2 RK_PA3 9 &pcfg_pull_none>;
		};

		/omit-if-no-ref/
		uart5m2_rtsn_pins: uart5m2-rtsn-pins {
			rockchip,pins =
				<2 RK_PA2 9 &pcfg_pull_none>;
		};
	};

	uart6 {
		/omit-if-no-ref/
		uart6m0_xfer_pins: uart6m0-xfer-pins {
			rockchip,pins =
				<2 RK_PB0 9 &pcfg_pull_up>,
				<2 RK_PB1 9 &pcfg_pull_up>;
		};

		/omit-if-no-ref/
		uart6m0_ctsn_pins: uart6m0-ctsn-pins {
			rockchip,pins =
				<2 RK_PB3 12 &pcfg_pull_none>;
		};

		/omit-if-no-ref/
		uart6m0_rtsn_pins: uart6m0-rtsn-pins {
			rockchip,pins =
				<2 RK_PB2 12 &pcfg_pull_none>;
		};

		/omit-if-no-ref/
		uart6m1_xfer_pins: uart6m1-xfer-pins {
			rockchip,pins =
				<4 RK_PB1 9 &pcfg_pull_up>,
				<4 RK_PB0 9 &pcfg_pull_up>;
		};

		/omit-if-no-ref/
		uart6m1_ctsn_pins: uart6m1-ctsn-pins {
			rockchip,pins =
				<4 RK_PB3 9 &pcfg_pull_none>;
		};

		/omit-if-no-ref/
		uart6m1_rtsn_pins: uart6m1-rtsn-pins {
			rockchip,pins =
				<4 RK_PB2 9 &pcfg_pull_none>;
		};

		/omit-if-no-ref/
		uart6m2_xfer_pins: uart6m2-xfer-pins {
			rockchip,pins =
				<1 RK_PB3 9 &pcfg_pull_up>,
				<1 RK_PB0 9 &pcfg_pull_up>;
		};

		/omit-if-no-ref/
		uart6m2_ctsn_pins: uart6m2-ctsn-pins {
			rockchip,pins =
				<1 RK_PA5 9 &pcfg_pull_none>;
		};

		/omit-if-no-ref/
		uart6m2_rtsn_pins: uart6m2-rtsn-pins {
			rockchip,pins =
				<1 RK_PA4 9 &pcfg_pull_none>;
		};
	};

	uart7 {
		/omit-if-no-ref/
		uart7m0_xfer_pins: uart7m0-xfer-pins {
			rockchip,pins =
				<1 RK_PD1 9 &pcfg_pull_up>,
				<1 RK_PD0 9 &pcfg_pull_up>;
		};

		/omit-if-no-ref/
		uart7m0_ctsn_pins: uart7m0-ctsn-pins {
			rockchip,pins =
				<1 RK_PD5 9 &pcfg_pull_none>;
		};

		/omit-if-no-ref/
		uart7m0_rtsn_pins: uart7m0-rtsn-pins {
			rockchip,pins =
				<1 RK_PD4 9 &pcfg_pull_none>;
		};

		/omit-if-no-ref/
		uart7m1_xfer_pins: uart7m1-xfer-pins {
			rockchip,pins =
				<1 RK_PA3 9 &pcfg_pull_up>,
				<1 RK_PA2 9 &pcfg_pull_up>;
		};

		/omit-if-no-ref/
		uart7m1_ctsn_pins: uart7m1-ctsn-pins {
			rockchip,pins =
				<1 RK_PA1 9 &pcfg_pull_none>;
		};

		/omit-if-no-ref/
		uart7m1_rtsn_pins: uart7m1-rtsn-pins {
			rockchip,pins =
				<1 RK_PA0 9 &pcfg_pull_none>;
		};

		/omit-if-no-ref/
		uart7m2_xfer_pins: uart7m2-xfer-pins {
			rockchip,pins =
				<2 RK_PA0 14 &pcfg_pull_up>,
				<2 RK_PA1 14 &pcfg_pull_up>;
		};
	};

	uart8 {
		/omit-if-no-ref/
		uart8m0_xfer_pins: uart8m0-xfer-pins {
			rockchip,pins =
				<3 RK_PC5 9 &pcfg_pull_up>,
				<3 RK_PC6 9 &pcfg_pull_up>;
		};

		/omit-if-no-ref/
		uart8m0_ctsn_pins: uart8m0-ctsn-pins {
			rockchip,pins =
				<3 RK_PD0 9 &pcfg_pull_none>;
		};

		/omit-if-no-ref/
		uart8m0_rtsn_pins: uart8m0-rtsn-pins {
			rockchip,pins =
				<3 RK_PC7 9 &pcfg_pull_none>;
		};

		/omit-if-no-ref/
		uart8m1_xfer_pins: uart8m1-xfer-pins {
			rockchip,pins =
				<0 RK_PC2 9 &pcfg_pull_up>,
				<0 RK_PC1 9 &pcfg_pull_up>;
		};

		/omit-if-no-ref/
		uart8m1_ctsn_pins: uart8m1-ctsn-pins {
			rockchip,pins =
				<0 RK_PC7 9 &pcfg_pull_none>;
		};

		/omit-if-no-ref/
		uart8m1_rtsn_pins: uart8m1-rtsn-pins {
			rockchip,pins =
				<0 RK_PC6 9 &pcfg_pull_none>;
		};
	};

	uart9 {
		/omit-if-no-ref/
		uart9m0_xfer_pins: uart9m0-xfer-pins {
			rockchip,pins =
				<4 RK_PB5 9 &pcfg_pull_up>,
				<4 RK_PB4 9 &pcfg_pull_up>;
		};

		/omit-if-no-ref/
		uart9m0_ctsn_pins: uart9m0-ctsn-pins {
			rockchip,pins =
				<4 RK_PB6 9 &pcfg_pull_none>;
		};

		/omit-if-no-ref/
		uart9m0_rtsn_pins: uart9m0-rtsn-pins {
			rockchip,pins =
				<4 RK_PB7 9 &pcfg_pull_none>;
		};

		/omit-if-no-ref/
		uart9m1_xfer_pins: uart9m1-xfer-pins {
			rockchip,pins =
				<4 RK_PA1 9 &pcfg_pull_up>,
				<4 RK_PA0 9 &pcfg_pull_up>;
		};

		/omit-if-no-ref/
		uart9m1_ctsn_pins: uart9m1-ctsn-pins {
			rockchip,pins =
				<3 RK_PB7 10 &pcfg_pull_none>;
		};

		/omit-if-no-ref/
		uart9m1_rtsn_pins: uart9m1-rtsn-pins {
			rockchip,pins =
				<3 RK_PC0 10 &pcfg_pull_none>;
		};

		/omit-if-no-ref/
		uart9m2_xfer_pins: uart9m2-xfer-pins {
			rockchip,pins =
				<2 RK_PB3 9 &pcfg_pull_up>,
				<2 RK_PB2 9 &pcfg_pull_up>;
		};
	};

	uart10 {
		/omit-if-no-ref/
		uart10m0_xfer_pins: uart10m0-xfer-pins {
			rockchip,pins =
				<3 RK_PB0 9 &pcfg_pull_up>,
				<3 RK_PB1 9 &pcfg_pull_up>;
		};

		/omit-if-no-ref/
		uart10m0_ctsn_pins: uart10m0-ctsn-pins {
			rockchip,pins =
				<3 RK_PA6 10 &pcfg_pull_none>;
		};

		/omit-if-no-ref/
		uart10m0_rtsn_pins: uart10m0-rtsn-pins {
			rockchip,pins =
				<3 RK_PA7 10 &pcfg_pull_none>;
		};

		/omit-if-no-ref/
		uart10m1_xfer_pins: uart10m1-xfer-pins {
			rockchip,pins =
				<2 RK_PC5 9 &pcfg_pull_up>,
				<2 RK_PC4 9 &pcfg_pull_up>;
		};

		/omit-if-no-ref/
		uart10m1_ctsn_pins: uart10m1-ctsn-pins {
			rockchip,pins =
				<2 RK_PC6 9 &pcfg_pull_none>;
		};

		/omit-if-no-ref/
		uart10m1_rtsn_pins: uart10m1-rtsn-pins {
			rockchip,pins =
				<2 RK_PC7 9 &pcfg_pull_none>;
		};

		/omit-if-no-ref/
		uart10m2_xfer_pins: uart10m2-xfer-pins {
			rockchip,pins =
				<0 RK_PC5 9 &pcfg_pull_up>,
				<0 RK_PC4 9 &pcfg_pull_up>;
		};
	};

	uart11 {
		/omit-if-no-ref/
		uart11m0_xfer_pins: uart11m0-xfer-pins {
			rockchip,pins =
				<0 RK_PD1 9 &pcfg_pull_up>,
				<0 RK_PD0 9 &pcfg_pull_up>;
		};

		/omit-if-no-ref/
		uart11m1_xfer_pins: uart11m1-xfer-pins {
			rockchip,pins =
				<2 RK_PB7 9 &pcfg_pull_up>,
				<2 RK_PB6 9 &pcfg_pull_up>;
		};

		/omit-if-no-ref/
		uart11m2_xfer_pins: uart11m2-xfer-pins {
			rockchip,pins =
				<2 RK_PC7 12 &pcfg_pull_up>,
				<2 RK_PC6 12 &pcfg_pull_up>;
		};
	};

	ufs {
		/omit-if-no-ref/
		ufs_refclk_pins: ufs-refclk-pins {
			rockchip,pins =
				<4 RK_PC1 1 &pcfg_pull_none>;
		};

		/omit-if-no-ref/
		ufs_rst_pins: ufs-rst-pins {
			rockchip,pins =
				<4 RK_PC0 1 &pcfg_pull_none>;
		};
	};

	vi_cif {
		/omit-if-no-ref/
		vi_cif_pins: vi-cif-pins {
			rockchip,pins =
				<2 RK_PD7 6 &pcfg_pull_none>,
				<2 RK_PD6 6 &pcfg_pull_none>,
				<2 RK_PD3 6 &pcfg_pull_none>,
				<2 RK_PD2 6 &pcfg_pull_none>,
				<2 RK_PD1 6 &pcfg_pull_none>,
				<2 RK_PD0 6 &pcfg_pull_none>,
				<2 RK_PC7 6 &pcfg_pull_none>,
				<2 RK_PC6 6 &pcfg_pull_none>,
				<2 RK_PC5 6 &pcfg_pull_none>,
				<2 RK_PC4 6 &pcfg_pull_none>,
				<2 RK_PC1 2 &pcfg_pull_none>,
				<2 RK_PC0 2 &pcfg_pull_none>,
				<2 RK_PB7 2 &pcfg_pull_none>,
				<2 RK_PB6 2 &pcfg_pull_none>,
				<2 RK_PB5 2 &pcfg_pull_none>,
				<2 RK_PB4 2 &pcfg_pull_none>,
				<2 RK_PB3 2 &pcfg_pull_none>,
				<2 RK_PB2 2 &pcfg_pull_none>,
				<2 RK_PD4 6 &pcfg_pull_none>,
				<2 RK_PD5 6 &pcfg_pull_none>;
		};
	};

	vo_ebc {
		/omit-if-no-ref/
		vo_ebc_pins: vo-ebc-pins {
			rockchip,pins =
				<4 RK_PA0 4 &pcfg_pull_none>,
				<4 RK_PA1 4 &pcfg_pull_none>,
				<3 RK_PD5 4 &pcfg_pull_none>,
				<3 RK_PA6 4 &pcfg_pull_none>,
				<3 RK_PA5 4 &pcfg_pull_none>,
				<3 RK_PB3 4 &pcfg_pull_none>,
				<3 RK_PB2 4 &pcfg_pull_none>,
				<3 RK_PB1 4 &pcfg_pull_none>,
				<3 RK_PB0 4 &pcfg_pull_none>,
				<3 RK_PD6 4 &pcfg_pull_none>,
				<3 RK_PD3 4 &pcfg_pull_none>,
				<3 RK_PD2 4 &pcfg_pull_none>,
				<3 RK_PD1 4 &pcfg_pull_none>,
				<3 RK_PD0 4 &pcfg_pull_none>,
				<3 RK_PC7 4 &pcfg_pull_none>,
				<3 RK_PC6 4 &pcfg_pull_none>,
				<3 RK_PC5 4 &pcfg_pull_none>,
				<3 RK_PC4 4 &pcfg_pull_none>,
				<3 RK_PC3 4 &pcfg_pull_none>,
				<3 RK_PC2 4 &pcfg_pull_none>,
				<3 RK_PC1 4 &pcfg_pull_none>,
				<3 RK_PC0 4 &pcfg_pull_none>,
				<3 RK_PB7 4 &pcfg_pull_none>,
				<3 RK_PB6 4 &pcfg_pull_none>,
				<3 RK_PB5 4 &pcfg_pull_none>,
				<3 RK_PB4 4 &pcfg_pull_none>,
				<4 RK_PB0 5 &pcfg_pull_none>,
				<4 RK_PB1 5 &pcfg_pull_none>,
				<4 RK_PB2 5 &pcfg_pull_none>,
				<4 RK_PB3 5 &pcfg_pull_none>,
				<4 RK_PB4 5 &pcfg_pull_none>,
				<4 RK_PB5 5 &pcfg_pull_none>,
				<4 RK_PB6 5 &pcfg_pull_none>,
				<4 RK_PB7 5 &pcfg_pull_none>,
				<3 RK_PD4 4 &pcfg_pull_none>,
				<3 RK_PD7 4 &pcfg_pull_none>,
				<3 RK_PA4 4 &pcfg_pull_none>,
				<3 RK_PA7 4 &pcfg_pull_none>;
		};
	};

	vo_lcdc {
		/omit-if-no-ref/
		vo_lcdc_pins: vo-lcdc-pins {
			rockchip,pins =
				<3 RK_PD7 3 &pcfg_pull_none>,
				<3 RK_PD3 3 &pcfg_pull_none>,
				<3 RK_PD2 3 &pcfg_pull_none>,
				<3 RK_PD1 3 &pcfg_pull_none>,
				<3 RK_PD0 3 &pcfg_pull_none>,
				<3 RK_PC7 3 &pcfg_pull_none>,
				<3 RK_PC6 3 &pcfg_pull_none>,
				<3 RK_PC5 3 &pcfg_pull_none>,
				<3 RK_PC4 3 &pcfg_pull_none>,
				<3 RK_PC3 3 &pcfg_pull_none>,
				<3 RK_PC2 3 &pcfg_pull_none>,
				<3 RK_PC1 3 &pcfg_pull_none>,
				<3 RK_PC0 3 &pcfg_pull_none>,
				<3 RK_PB7 3 &pcfg_pull_none>,
				<3 RK_PB6 3 &pcfg_pull_none>,
				<3 RK_PB5 3 &pcfg_pull_none>,
				<3 RK_PB4 3 &pcfg_pull_none>,
				<3 RK_PB3 3 &pcfg_pull_none>,
				<3 RK_PB2 3 &pcfg_pull_none>,
				<3 RK_PB1 3 &pcfg_pull_none>,
				<3 RK_PB0 3 &pcfg_pull_none>,
				<3 RK_PA7 3 &pcfg_pull_none>,
				<3 RK_PA6 3 &pcfg_pull_none>,
				<3 RK_PA5 3 &pcfg_pull_none>,
				<3 RK_PA4 3 &pcfg_pull_none>,
				<3 RK_PD4 3 &pcfg_pull_none>,
				<3 RK_PD5 3 &pcfg_pull_none>,
				<3 RK_PD6 3 &pcfg_pull_none>;
		};
	};

	vo_post {
		/omit-if-no-ref/
		vo_post_pins: vo-post-pins {
			rockchip,pins =
				<4 RK_PA1 3 &pcfg_pull_none>;
		};
	};

	vp0_sync {
		/omit-if-no-ref/
		vp0_sync_pins: vp0-sync-pins {
			rockchip,pins =
				<4 RK_PB5 3 &pcfg_pull_none>;
		};
	};

	vp1_sync {
		/omit-if-no-ref/
		vp1_sync_pins: vp1-sync-pins {
			rockchip,pins =
				<4 RK_PB6 3 &pcfg_pull_none>;
		};
	};
};

&pinctrl {
	ebc {
		/omit-if-no-ref/
		ebc_24bit_pins: ebc-24bit-pins {
			rockchip,pins =
				<3 RK_PD5 4 &pcfg_pull_none>,
				<3 RK_PA6 4 &pcfg_pull_none>,
				<3 RK_PA5 4 &pcfg_pull_none>,
				<3 RK_PB3 4 &pcfg_pull_none>,
				<3 RK_PD6 4 &pcfg_pull_none>,
				<3 RK_PD3 4 &pcfg_pull_none>,
				<3 RK_PD2 4 &pcfg_pull_none>,
				<3 RK_PD1 4 &pcfg_pull_none>,
				<3 RK_PD0 4 &pcfg_pull_none>,
				<3 RK_PC7 4 &pcfg_pull_none>,
				<3 RK_PC6 4 &pcfg_pull_none>,
				<3 RK_PC5 4 &pcfg_pull_none>,
				<3 RK_PC4 4 &pcfg_pull_none>,
				<3 RK_PC3 4 &pcfg_pull_none>,
				<3 RK_PC2 4 &pcfg_pull_none>,
				<3 RK_PC1 4 &pcfg_pull_none>,
				<3 RK_PC0 4 &pcfg_pull_none>,
				<3 RK_PB7 4 &pcfg_pull_none>,
				<3 RK_PB6 4 &pcfg_pull_none>,
				<3 RK_PB5 4 &pcfg_pull_none>,
				<3 RK_PB4 4 &pcfg_pull_none>,
				<4 RK_PB0 5 &pcfg_pull_none>,
				<4 RK_PB1 5 &pcfg_pull_none>,
				<4 RK_PB2 5 &pcfg_pull_none>,
				<4 RK_PB3 5 &pcfg_pull_none>,
				<4 RK_PB4 5 &pcfg_pull_none>,
				<4 RK_PB5 5 &pcfg_pull_none>,
				<4 RK_PB6 5 &pcfg_pull_none>,
				<4 RK_PB7 5 &pcfg_pull_none>,
				<3 RK_PD4 4 &pcfg_pull_none>,
				<3 RK_PD7 4 &pcfg_pull_none>;
		};

		/omit-if-no-ref/
		ebc_16bit_pins: ebc-16bit-pins {
			rockchip,pins =
				<3 RK_PD5 4 &pcfg_pull_none>,
				<3 RK_PA6 4 &pcfg_pull_none>,
				<3 RK_PA5 4 &pcfg_pull_none>,
				<3 RK_PB3 4 &pcfg_pull_none>,
				<3 RK_PD6 4 &pcfg_pull_none>,
				<3 RK_PD3 4 &pcfg_pull_none>,
				<3 RK_PD2 4 &pcfg_pull_none>,
				<3 RK_PD1 4 &pcfg_pull_none>,
				<3 RK_PD0 4 &pcfg_pull_none>,
				<3 RK_PC7 4 &pcfg_pull_none>,
				<3 RK_PC6 4 &pcfg_pull_none>,
				<3 RK_PC5 4 &pcfg_pull_none>,
				<3 RK_PC4 4 &pcfg_pull_none>,
				<3 RK_PC3 4 &pcfg_pull_none>,
				<3 RK_PC2 4 &pcfg_pull_none>,
				<3 RK_PC1 4 &pcfg_pull_none>,
				<3 RK_PC0 4 &pcfg_pull_none>,
				<3 RK_PB7 4 &pcfg_pull_none>,
				<3 RK_PB6 4 &pcfg_pull_none>,
				<3 RK_PB5 4 &pcfg_pull_none>,
				<3 RK_PB4 4 &pcfg_pull_none>,
				<3 RK_PD4 4 &pcfg_pull_none>,
				<3 RK_PD7 4 &pcfg_pull_none>;
		};

		/omit-if-no-ref/
		ebc_8bit_pins: ebc-8bit-pins {
			rockchip,pins =
				<3 RK_PD5 4 &pcfg_pull_none>,
				<3 RK_PA6 4 &pcfg_pull_none>,
				<3 RK_PA5 4 &pcfg_pull_none>,
				<3 RK_PB3 4 &pcfg_pull_none>,
				<3 RK_PD6 4 &pcfg_pull_none>,
				<3 RK_PD3 4 &pcfg_pull_none>,
				<3 RK_PD2 4 &pcfg_pull_none>,
				<3 RK_PD1 4 &pcfg_pull_none>,
				<3 RK_PD0 4 &pcfg_pull_none>,
				<3 RK_PC7 4 &pcfg_pull_none>,
				<3 RK_PC6 4 &pcfg_pull_none>,
				<3 RK_PC5 4 &pcfg_pull_none>,
				<3 RK_PC4 4 &pcfg_pull_none>,
				<3 RK_PD4 4 &pcfg_pull_none>,
				<3 RK_PD7 4 &pcfg_pull_none>;
		};

		/omit-if-no-ref/
		ebc_extern: ebc-extern {
			rockchip,pins =
				<3 RK_PB2 4 &pcfg_pull_none>,
				<3 RK_PB1 4 &pcfg_pull_none>,
				<3 RK_PB0 4 &pcfg_pull_none>,
				<3 RK_PA4 4 &pcfg_pull_none>,
				<3 RK_PA7 4 &pcfg_pull_none>;
		};
	};

	pdm {
		/omit-if-no-ref/
		pdmm0_clk0_idle: pdmm0-clk0-idle {
			rockchip,pins =
				<0 RK_PC4 RK_FUNC_GPIO &pcfg_pull_none>;
		};

		/omit-if-no-ref/
		pdmm0_clk1_idle: pdmm0-clk1-idle {
			rockchip,pins =
				<0 RK_PC3 RK_FUNC_GPIO &pcfg_pull_none>;
		};

		/omit-if-no-ref/
		pdmm1_clk0_idle: pdmm1-clk0-idle {
			rockchip,pins =
				<2 RK_PB2 RK_FUNC_GPIO &pcfg_pull_none>;
		};

		/omit-if-no-ref/
		pdmm1_clk1_idle: pdmm1-clk1-idle {
			rockchip,pins =
				<2 RK_PB4 RK_FUNC_GPIO &pcfg_pull_none>;
		};

		/omit-if-no-ref/
		pdmm2_clk0_idle: pdmm1-clk0-idle {
			rockchip,pins =
				<1 RK_PC1 RK_FUNC_GPIO &pcfg_pull_none>;
		};

		/omit-if-no-ref/
		pdmm2_clk1_idle: pdmm1-clk1-idle {
			rockchip,pins =
				<1 RK_PD5 RK_FUNC_GPIO &pcfg_pull_none>;
		};

		/omit-if-no-ref/
		pdmm3_clk0_idle: pdmm1-clk0-idle {
			rockchip,pins =
				<2 RK_PC5 RK_FUNC_GPIO &pcfg_pull_none>;
		};

		/omit-if-no-ref/
		pdmm3_clk1_idle: pdmm1-clk1-idle {
			rockchip,pins =
				<2 RK_PC7 RK_FUNC_GPIO &pcfg_pull_none>;
		};

		/omit-if-no-ref/
		pdmm4_clk0_idle: pdmm1-clk0-idle {
			rockchip,pins =
				<3 RK_PB1 RK_FUNC_GPIO &pcfg_pull_none>;
		};

		/omit-if-no-ref/
		pdmm4_clk1_idle: pdmm1-clk1-idle {
			rockchip,pins =
				<3 RK_PA7 RK_FUNC_GPIO &pcfg_pull_none>;
		};
	};

	ufs {
		/omit-if-no-ref/
		ufs_rstgpio: ufs-rstgpio {
			rockchip,pins =
				<4 RK_PC0 RK_FUNC_GPIO &pcfg_pull_down>;
		};
	};

	vo {
		/omit-if-no-ref/
		bt1120_pins: bt1120-pins {
			rockchip,pins =
				<3 RK_PD7 3 &pcfg_pull_none>,
				<3 RK_PD0 3 &pcfg_pull_none>,
				<3 RK_PC7 3 &pcfg_pull_none>,
				<3 RK_PC6 3 &pcfg_pull_none>,
				<3 RK_PC5 3 &pcfg_pull_none>,
				<3 RK_PC4 3 &pcfg_pull_none>,
				<3 RK_PC1 3 &pcfg_pull_none>,
				<3 RK_PC0 3 &pcfg_pull_none>,
				<3 RK_PB7 3 &pcfg_pull_none>,
				<3 RK_PB6 3 &pcfg_pull_none>,
				<3 RK_PB5 3 &pcfg_pull_none>,
				<3 RK_PB4 3 &pcfg_pull_none>,
				<3 RK_PB0 3 &pcfg_pull_none>,
				<3 RK_PA7 3 &pcfg_pull_none>,
				<3 RK_PA6 3 &pcfg_pull_none>,
				<3 RK_PA5 3 &pcfg_pull_none>,
				<3 RK_PA4 3 &pcfg_pull_none>;
		};

		/omit-if-no-ref/
		bt656_pins: bt656-pins {
			rockchip,pins =
				<3 RK_PD7 3 &pcfg_pull_none>,
				<3 RK_PD0 3 &pcfg_pull_none>,
				<3 RK_PC7 3 &pcfg_pull_none>,
				<3 RK_PC6 3 &pcfg_pull_none>,
				<3 RK_PC5 3 &pcfg_pull_none>,
				<3 RK_PC4 3 &pcfg_pull_none>,
				<3 RK_PC1 3 &pcfg_pull_none>,
				<3 RK_PC0 3 &pcfg_pull_none>,
				<3 RK_PB7 3 &pcfg_pull_none>;
		};

		/omit-if-no-ref/
		rgb3x8_pins_m0: rgb3x8-pins-m0 {
			rockchip,pins =
				<3 RK_PD7 3 &pcfg_pull_none>,
				<3 RK_PD0 3 &pcfg_pull_none>,
				<3 RK_PC7 3 &pcfg_pull_none>,
				<3 RK_PC6 3 &pcfg_pull_none>,
				<3 RK_PC5 3 &pcfg_pull_none>,
				<3 RK_PC4 3 &pcfg_pull_none>,
				<3 RK_PC1 3 &pcfg_pull_none>,
				<3 RK_PC0 3 &pcfg_pull_none>,
				<3 RK_PB7 3 &pcfg_pull_none>,
				<3 RK_PD4 3 &pcfg_pull_none>,
				<3 RK_PD5 3 &pcfg_pull_none>,
				<3 RK_PD6 3 &pcfg_pull_none>;
		};

		/omit-if-no-ref/
		rgb3x8_pins_m1: rgb3x8-pins-m1 {
			rockchip,pins =
				<3 RK_PB6 3 &pcfg_pull_none>,
				<3 RK_PB5 3 &pcfg_pull_none>,
				<3 RK_PB4 3 &pcfg_pull_none>,
				<3 RK_PB0 3 &pcfg_pull_none>,
				<3 RK_PA7 3 &pcfg_pull_none>,
				<3 RK_PA6 3 &pcfg_pull_none>,
				<3 RK_PA5 3 &pcfg_pull_none>,
				<3 RK_PA4 3 &pcfg_pull_none>,
				<3 RK_PD4 3 &pcfg_pull_none>,
				<3 RK_PD5 3 &pcfg_pull_none>,
				<3 RK_PD6 3 &pcfg_pull_none>;
		};

		/omit-if-no-ref/
		rgb565_pins: rgb565-pins {
			rockchip,pins =
				<3 RK_PD7 3 &pcfg_pull_none>,
				<3 RK_PD0 3 &pcfg_pull_none>,
				<3 RK_PC7 3 &pcfg_pull_none>,
				<3 RK_PC6 3 &pcfg_pull_none>,
				<3 RK_PC5 3 &pcfg_pull_none>,
				<3 RK_PC4 3 &pcfg_pull_none>,
				<3 RK_PC1 3 &pcfg_pull_none>,
				<3 RK_PC0 3 &pcfg_pull_none>,
				<3 RK_PB7 3 &pcfg_pull_none>,
				<3 RK_PB6 3 &pcfg_pull_none>,
				<3 RK_PB5 3 &pcfg_pull_none>,
				<3 RK_PB4 3 &pcfg_pull_none>,
				<3 RK_PB0 3 &pcfg_pull_none>,
				<3 RK_PA7 3 &pcfg_pull_none>,
				<3 RK_PA6 3 &pcfg_pull_none>,
				<3 RK_PA5 3 &pcfg_pull_none>,
				<3 RK_PA4 3 &pcfg_pull_none>,
				<3 RK_PD4 3 &pcfg_pull_none>,
				<3 RK_PD5 3 &pcfg_pull_none>,
				<3 RK_PD6 3 &pcfg_pull_none>;
		};

		/omit-if-no-ref/
		rgb666_pins: rgb666-pins {
			rockchip,pins =
				<3 RK_PD7 3 &pcfg_pull_none>,
				<3 RK_PD1 3 &pcfg_pull_none>,
				<3 RK_PD0 3 &pcfg_pull_none>,
				<3 RK_PC7 3 &pcfg_pull_none>,
				<3 RK_PC6 3 &pcfg_pull_none>,
				<3 RK_PC5 3 &pcfg_pull_none>,
				<3 RK_PC4 3 &pcfg_pull_none>,
				<3 RK_PC1 3 &pcfg_pull_none>,
				<3 RK_PC0 3 &pcfg_pull_none>,
				<3 RK_PB7 3 &pcfg_pull_none>,
				<3 RK_PB6 3 &pcfg_pull_none>,
				<3 RK_PB5 3 &pcfg_pull_none>,
				<3 RK_PB4 3 &pcfg_pull_none>,
				<3 RK_PB1 3 &pcfg_pull_none>,
				<3 RK_PB0 3 &pcfg_pull_none>,
				<3 RK_PA7 3 &pcfg_pull_none>,
				<3 RK_PA6 3 &pcfg_pull_none>,
				<3 RK_PA5 3 &pcfg_pull_none>,
				<3 RK_PA4 3 &pcfg_pull_none>,
				<3 RK_PD4 3 &pcfg_pull_none>,
				<3 RK_PD5 3 &pcfg_pull_none>,
				<3 RK_PD6 3 &pcfg_pull_none>;
		};

		/omit-if-no-ref/
		rgb888_pins: rgb888-pins {
			rockchip,pins =
				<3 RK_PD7 3 &pcfg_pull_none>,
				<3 RK_PD3 3 &pcfg_pull_none>,
				<3 RK_PD2 3 &pcfg_pull_none>,
				<3 RK_PD1 3 &pcfg_pull_none>,
				<3 RK_PD0 3 &pcfg_pull_none>,
				<3 RK_PC7 3 &pcfg_pull_none>,
				<3 RK_PC6 3 &pcfg_pull_none>,
				<3 RK_PC5 3 &pcfg_pull_none>,
				<3 RK_PC4 3 &pcfg_pull_none>,
				<3 RK_PC3 3 &pcfg_pull_none>,
				<3 RK_PC2 3 &pcfg_pull_none>,
				<3 RK_PC1 3 &pcfg_pull_none>,
				<3 RK_PC0 3 &pcfg_pull_none>,
				<3 RK_PB7 3 &pcfg_pull_none>,
				<3 RK_PB6 3 &pcfg_pull_none>,
				<3 RK_PB5 3 &pcfg_pull_none>,
				<3 RK_PB4 3 &pcfg_pull_none>,
				<3 RK_PB3 3 &pcfg_pull_none>,
				<3 RK_PB2 3 &pcfg_pull_none>,
				<3 RK_PB1 3 &pcfg_pull_none>,
				<3 RK_PB0 3 &pcfg_pull_none>,
				<3 RK_PA7 3 &pcfg_pull_none>,
				<3 RK_PA6 3 &pcfg_pull_none>,
				<3 RK_PA5 3 &pcfg_pull_none>,
				<3 RK_PA4 3 &pcfg_pull_none>,
				<3 RK_PD4 3 &pcfg_pull_none>,
				<3 RK_PD5 3 &pcfg_pull_none>,
				<3 RK_PD6 3 &pcfg_pull_none>;
		};
	};
};
